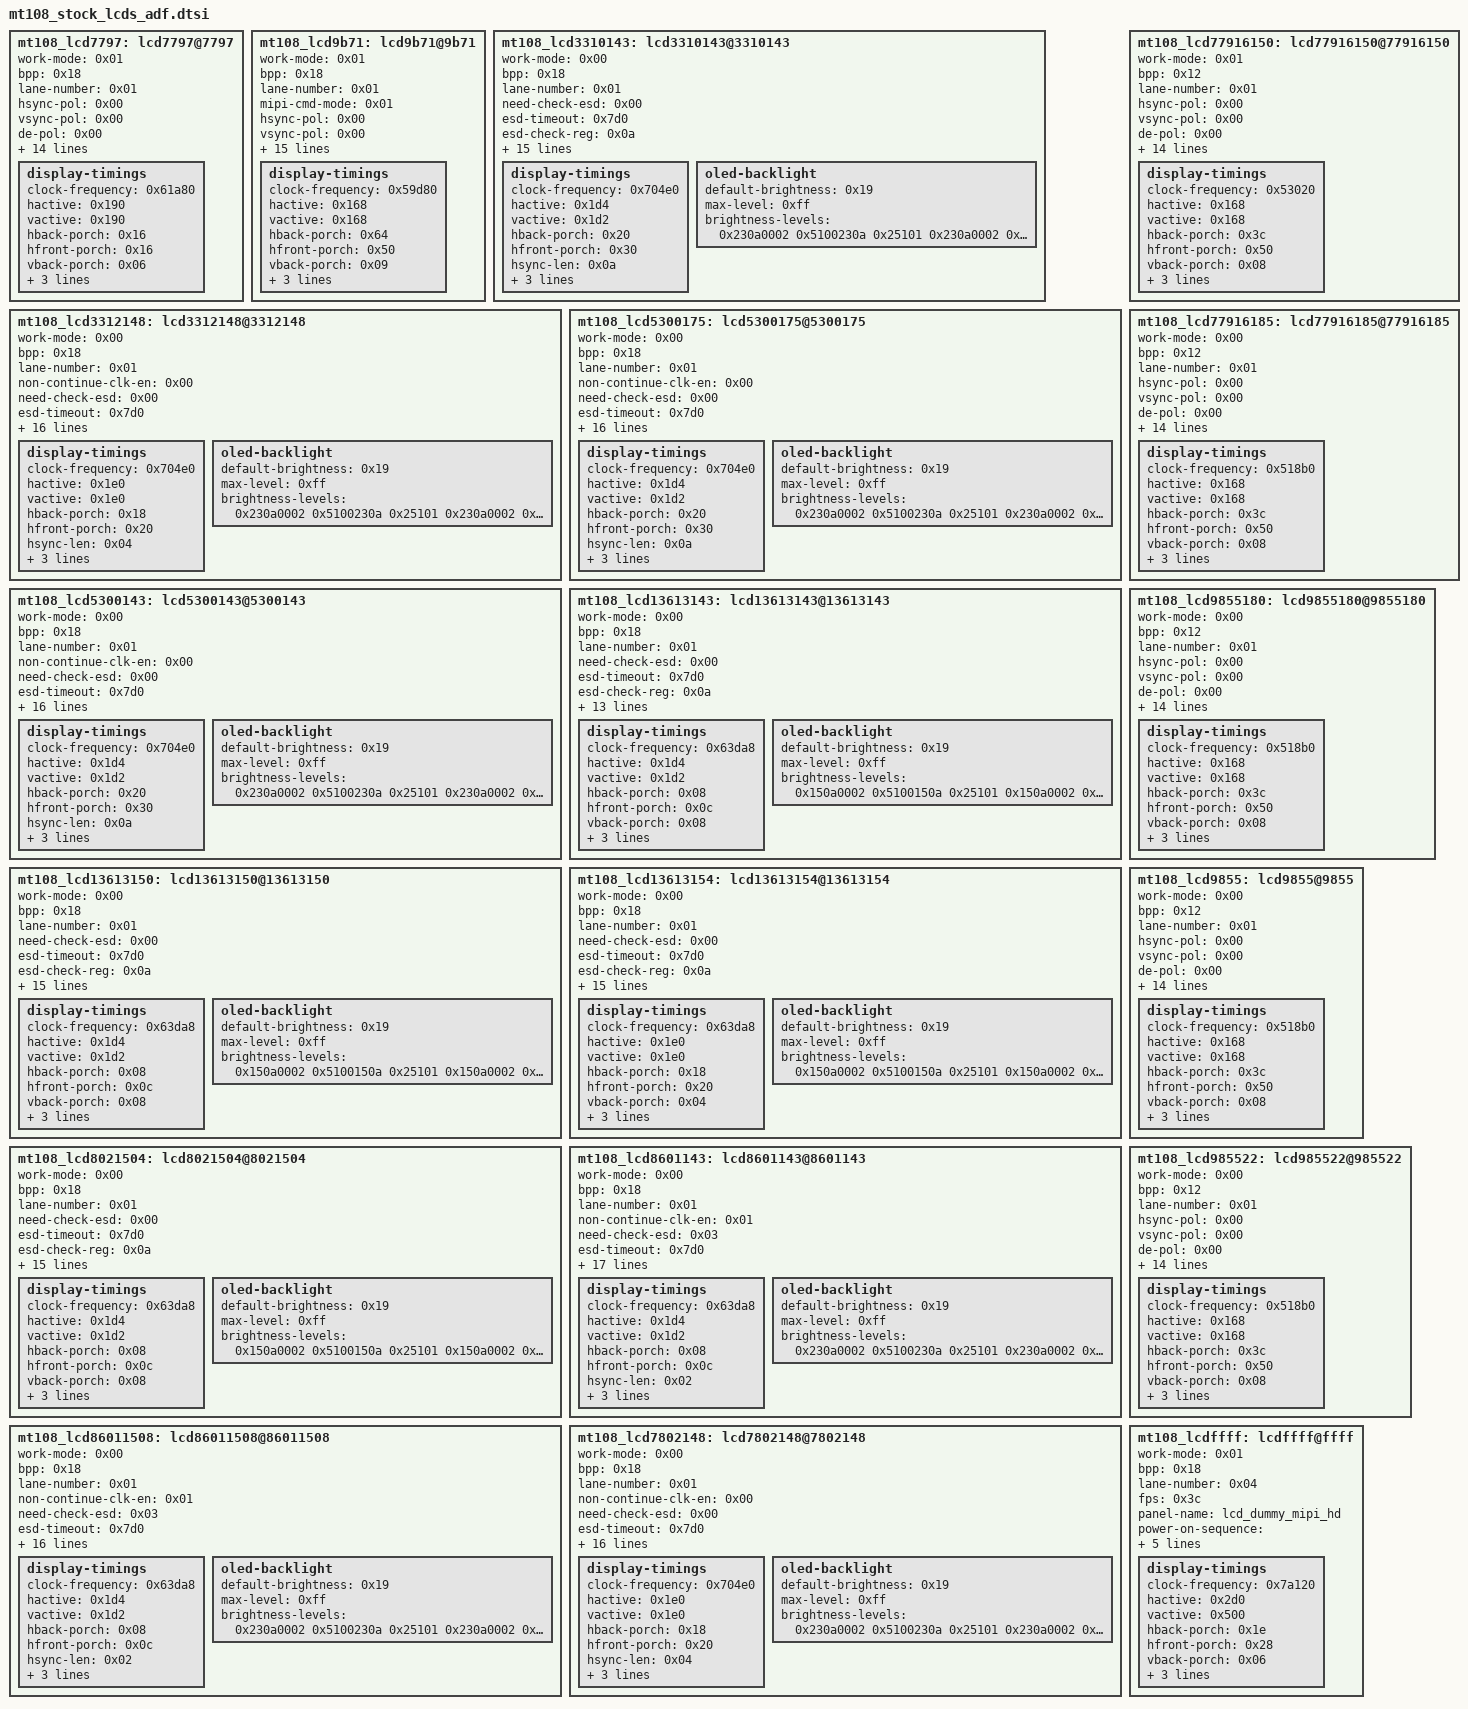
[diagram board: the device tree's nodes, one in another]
// SPDX-License-Identifier: GPL-2.0
/*
 * Stock /lcds panel nodes, generated by devices/stock_lcds_to_dtsi.py
 * from the stock DT; include inside a "lcds" node.
 */

	mt108_lcd7797: lcd7797@7797 {
		work-mode = <0x01>;
		bpp = <0x18>;
		lane-number = <0x01>;
		hsync-pol = <0x00>;
		vsync-pol = <0x00>;
		de-pol = <0x00>;
		te-pol = <0x00>;
		color-mode-pol = <0x01>;
		shut-down-pol = <0x01>;
		need-check-esd = <0x00>;
		esd-timeout = <0x3e8>;
		fps = <0x3c>;
		panel-name = "lcd_st7797_mipi";
		power-on-sequence = <0x32 0x01 0x05 0x32 0x00 0x05 0x32 0x01 0x14>;
		power-off-sequence = <0x32 0x00 0x14>;
		init-data = [23 00 00 02 f0 c3 23 00 00 02 f0 96 23 00 00 02 f0 a5 29 00 00 05 c1 bb 02 0f 0b 29 00 00 05 c2 bb 02 0f 0b 29 00 00 05 c3 11 03 24 01 29 00 00 05 c4 11 03 24 01 23 00 00 02 c5 2e 29 00 00 0f e0 f0 05 0a 0c 0a 07 34 73 4b 0e 1b 19 29 2a 29 00 00 0f e1 f0 05 0a 0c 0a 06 33 03 4c 0e 1c 1a 29 2a 29 00 00 03 e4 c8 20 29 00 00 0d e5 0f f5 00 11 22 25 10 77 77 77 44 44 29 00 00 0d e6 0f f5 00 11 22 25 10 22 22 22 22 22 29 00 00 08 e7 00 77 1f cc 2a 80 33 29 00 00 08 ec 00 55 00 00 00 49 22 23 00 00 02 ed c3 29 00 00 03 e4 08 2f 23 00 00 02 b2 10 23 00 00 02 b3 02 23 00 00 02 b4 02 29 00 00 05 b5 00 54 00 54 29 00 00 03 b6 c7 31 29 00 00 08 ba 5b aa 02 00 21 01 00 29 00 00 09 bb 00 28 00 28 08 07 07 04 29 00 00 09 bc 00 36 00 28 08 07 07 04 29 00 00 0c bd 77 ff ff ff ba ab ff ff 16 ff 02 29 00 00 04 a4 c0 4a e0 29 00 00 0a a5 20 12 40 01 00 06 2a 0a 00 29 00 00 0a a6 20 12 40 01 00 06 2a 0a 00 23 00 00 02 d9 22 13 00 00 01 21 23 00 00 02 35 00 23 00 00 02 36 0c 23 00 00 02 3a 07 23 78 00 02 11 00 23 78 00 02 29 00];
		sleep-in = [13 0a 00 01 28 13 78 00 01 10];
		sleep-out = [13 78 00 01 11 13 64 00 01 29];

		display-timings {
			clock-frequency = <0x61a80>;
			hactive = <0x190>;
			vactive = <0x190>;
			hback-porch = <0x16>;
			hfront-porch = <0x16>;
			vback-porch = <0x06>;
			vfront-porch = <0x06>;
			hsync-len = <0x0a>;
			vsync-len = <0x02>;
		};
	};

	mt108_lcd9b71: lcd9b71@9b71 {
		work-mode = <0x01>;
		bpp = <0x18>;
		lane-number = <0x01>;
		mipi-cmd-mode = <0x01>;
		hsync-pol = <0x00>;
		vsync-pol = <0x00>;
		de-pol = <0x00>;
		te-pol = <0x00>;
		color-mode-pol = <0x01>;
		shut-down-pol = <0x01>;
		need-check-esd = <0x00>;
		esd-timeout = <0x3e8>;
		fps = <0x3b>;
		panel-name = "lcd_gc9b71_mipi_boe1389";
		power-on-sequence = <0x32 0x01 0x32 0x32 0x00 0x32 0x32 0x01 0x78>;
		power-off-sequence = <0x32 0x00 0x78>;
		init-data = [05 00 00 01 fe 05 00 00 01 ef 15 00 00 02 80 19 15 00 00 02 81 30 15 00 00 02 82 09 15 00 00 02 83 03 15 00 00 02 84 73 15 00 00 02 89 18 15 00 00 02 8a 40 15 00 00 02 8b 0a 15 00 00 02 3a 07 15 00 00 02 36 00 15 00 00 02 ec 07 39 00 00 08 74 01 68 d8 00 00 4e 00 15 00 00 02 98 3e 15 00 00 02 99 3e 39 00 00 03 a1 01 04 39 00 00 03 a2 01 04 15 00 00 02 cb 02 39 00 00 03 7c b6 24 15 00 00 02 ac 34 15 00 00 02 f6 c8 39 00 00 03 b5 0c 0c 39 00 00 03 eb 01 67 15 00 00 02 b0 81 39 00 00 03 73 10 03 39 00 00 05 60 38 0e 1f 56 39 00 00 05 63 38 10 1f 56 39 00 00 07 64 38 12 72 ea 1f 56 39 00 00 07 66 38 16 72 ee 1f 56 39 00 00 08 68 00 0a ee 0a ee 1c 1c 39 00 00 08 69 00 0a f2 0a f2 1c 1c 39 05 00 21 6e 07 01 1a 00 0b 0b 09 09 13 13 11 11 19 1e 1d 00 00 1d 1e 19 12 12 14 14 0a 0a 0c 0c 00 1a 02 08 39 00 00 08 6c cc 0c cc 84 cc 04 50 15 00 00 02 7d 72 15 00 00 02 b4 0a 39 00 00 0b 70 02 03 09 07 09 03 09 07 09 03 39 00 00 05 90 06 06 05 06 39 00 00 04 93 45 ff 00 39 00 00 03 fb 00 00 39 00 00 03 fb 00 00 15 00 00 02 c3 16 15 00 00 02 c4 30 15 00 00 02 c9 3f 39 01 00 07 f0 4f 0d 0a 0f 00 34 39 01 00 07 f2 4f 0e 09 0e 00 35 39 01 00 07 f1 49 93 7c 2d 2f ff 39 01 00 07 f3 49 92 7c 2d 2f ff 15 00 00 02 be 11 05 00 00 01 fe 05 00 00 01 ee 05 78 00 01 11 05 14 00 01 29 39 00 00 05 2c 00 00 00 00 39 14 00 05 2c 00 00 00 00];
		sleep-in = [05 0a 00 01 28 05 78 00 01 10];
		sleep-out = [05 78 00 01 11 05 64 00 01 29];

		display-timings {
			clock-frequency = <0x59d80>;
			hactive = <0x168>;
			vactive = <0x168>;
			hback-porch = <0x64>;
			hfront-porch = <0x50>;
			vback-porch = <0x09>;
			vfront-porch = <0x08>;
			hsync-len = <0x1e>;
			vsync-len = <0x02>;
		};
	};

	mt108_lcd3310143: lcd3310143@3310143 {
		work-mode = <0x00>;
		bpp = <0x18>;
		lane-number = <0x01>;
		need-check-esd = <0x00>;
		esd-timeout = <0x7d0>;
		esd-check-reg = <0x0a>;
		esd-return-code = <0x9c>;
		fps = <0x3c>;
		width-mm = <0x44>;
		height-mm = <0x79>;
		panel-name = "lcd_icna3310_oled143_mipi";
		power-on-sequence = <0x21 0x01 0x14 0x32 0x01 0x14 0x32 0x00 0x14 0x32 0x01 0x32>;
		power-off-sequence = <0x32 0x00 0x14 0x21 0x00 0x14>;
		init-data = [23 00 00 02 fe 20 23 00 00 02 f4 5a 23 00 00 02 f5 59 23 00 00 02 fe e0 23 00 00 02 02 20 23 00 00 02 04 25 23 00 00 02 0b 20 23 00 00 02 0c 25 23 00 00 02 11 14 23 00 00 02 fe 00 23 00 00 02 35 00 23 00 00 02 3a 77 23 00 00 02 51 00 23 00 00 02 53 20 23 00 00 02 63 ff 29 00 00 05 2a 00 06 01 d9 29 00 00 05 2b 00 00 01 d1 13 78 00 01 11 13 14 00 01 29];
		aod-in = [23 00 00 02 fe 00 13 0a 00 01 39];
		aod-out = [23 00 00 02 fe 00 13 0a 00 01 38];
		sleep-in = [13 0a 00 01 28 13 78 00 01 10];
		sleep-out = [13 78 00 01 11 13 32 00 01 29];

		display-timings {
			clock-frequency = <0x704e0>;
			hactive = <0x1d4>;
			vactive = <0x1d2>;
			hback-porch = <0x20>;
			hfront-porch = <0x30>;
			hsync-len = <0x0a>;
			vfront-porch = <0x08>;
			vback-porch = <0x04>;
			vsync-len = <0x02>;
		};

		oled-backlight {
			default-brightness = <0x19>;
			max-level = <0xff>;
			brightness-levels = <0x230a0002 0x5100230a 0x25101 0x230a0002 0x5102230a 0x25103 0x230a0002 0x5104230a 0x25105 0x230a0002 0x5106230a 0x25107 0x230a0002 0x5108230a 0x25109 0x230a0002 0x510a230a 0x2510b 0x230a0002 0x510c230a 0x2510d 0x230a0002 0x510e230a 0x2510f 0x230a0002 0x5110230a 0x25111 0x230a0002 0x5112230a 0x25113 0x230a0002 0x5114230a 0x25115 0x230a0002 0x5116230a 0x25117 0x230a0002 0x5118230a 0x25119 0x230a0002 0x511a230a 0x2511b 0x230a0002 0x511c230a 0x2511d 0x230a0002 0x511e230a 0x2511f 0x230a0002 0x5120230a 0x25121 0x230a0002 0x5122230a 0x25123 0x230a0002 0x5124230a 0x25125 0x230a0002 0x5126230a 0x25127 0x230a0002 0x5128230a 0x25129 0x230a0002 0x512a230a 0x2512b 0x230a0002 0x512c230a 0x2512d 0x230a0002 0x512e230a 0x2512f 0x230a0002 0x5130230a 0x25131 0x230a0002 0x5132230a 0x25133 0x230a0002 0x5134230a 0x25135 0x230a0002 0x5136230a 0x25137 0x230a0002 0x5138230a 0x25139 0x230a0002 0x513a230a 0x2513b 0x230a0002 0x513c230a 0x2513d 0x230a0002 0x513e230a 0x2513f 0x230a0002 0x5140230a 0x25141 0x230a0002 0x5142230a 0x25143 0x230a0002 0x5144230a 0x25145 0x230a0002 0x5146230a 0x25147 0x230a0002 0x5148230a 0x25149 0x230a0002 0x514a230a 0x2514b 0x230a0002 0x514c230a 0x2514d 0x230a0002 0x514e230a 0x2514f 0x230a0002 0x5150230a 0x25151 0x230a0002 0x5152230a 0x25153 0x230a0002 0x5154230a 0x25155 0x230a0002 0x5156230a 0x25157 0x230a0002 0x5158230a 0x25159 0x230a0002 0x515a230a 0x2515b 0x230a0002 0x515c230a 0x2515d 0x230a0002 0x515e230a 0x2515f 0x230a0002 0x5160230a 0x25161 0x230a0002 0x5162230a 0x25163 0x230a0002 0x5164230a 0x25165 0x230a0002 0x5166230a 0x25167 0x230a0002 0x5168230a 0x25169 0x230a0002 0x516a230a 0x2516b 0x230a0002 0x516c230a 0x2516d 0x230a0002 0x516e230a 0x2516f 0x230a0002 0x5170230a 0x25171 0x230a0002 0x5172230a 0x25173 0x230a0002 0x5174230a 0x25175 0x230a0002 0x5176230a 0x25177 0x230a0002 0x5178230a 0x25179 0x230a0002 0x517a230a 0x2517b 0x230a0002 0x517c230a 0x2517d 0x230a0002 0x517e230a 0x2517f 0x230a0002 0x5180230a 0x25181 0x230a0002 0x5182230a 0x25183 0x230a0002 0x5184230a 0x25185 0x230a0002 0x5186230a 0x25187 0x230a0002 0x5188230a 0x25189 0x230a0002 0x518a230a 0x2518b 0x230a0002 0x518c230a 0x2518d 0x230a0002 0x518e230a 0x2518f 0x230a0002 0x5190230a 0x25191 0x230a0002 0x5192230a 0x25193 0x230a0002 0x5194230a 0x25195 0x230a0002 0x5196230a 0x25197 0x230a0002 0x5198230a 0x25199 0x230a0002 0x519a230a 0x2519b 0x230a0002 0x519c230a 0x2519d 0x230a0002 0x519e230a 0x2519f 0x230a0002 0x51a0230a 0x251a1 0x230a0002 0x51a2230a 0x251a3 0x230a0002 0x51a4230a 0x251a5 0x230a0002 0x51a6230a 0x251a7 0x230a0002 0x51a8230a 0x251a9 0x230a0002 0x51aa230a 0x251ab 0x230a0002 0x51ac230a 0x251ad 0x230a0002 0x51ae230a 0x251af 0x230a0002 0x51b0230a 0x251b1 0x230a0002 0x51b2230a 0x251b3 0x230a0002 0x51b4230a 0x251b5 0x230a0002 0x51b6230a 0x251b7 0x230a0002 0x51b8230a 0x251b9 0x230a0002 0x51ba230a 0x251bb 0x230a0002 0x51bc230a 0x251bd 0x230a0002 0x51be230a 0x251bf 0x230a0002 0x51c0230a 0x251c1 0x230a0002 0x51c2230a 0x251c3 0x230a0002 0x51c4230a 0x251c5 0x230a0002 0x51c6230a 0x251c7 0x230a0002 0x51c8230a 0x251c9 0x230a0002 0x51ca230a 0x251cb 0x230a0002 0x51cc230a 0x251cd 0x230a0002 0x51ce230a 0x251cf 0x230a0002 0x51d0230a 0x251d1 0x230a0002 0x51d2230a 0x251d3 0x230a0002 0x51d4230a 0x251d5 0x230a0002 0x51d6230a 0x251d7 0x230a0002 0x51d8230a 0x251d9 0x230a0002 0x51da230a 0x251db 0x230a0002 0x51dc230a 0x251dd 0x230a0002 0x51de230a 0x251df 0x230a0002 0x51e0230a 0x251e1 0x230a0002 0x51e2230a 0x251e3 0x230a0002 0x51e4230a 0x251e5 0x230a0002 0x51e6230a 0x251e7 0x230a0002 0x51e8230a 0x251e9 0x230a0002 0x51ea230a 0x251eb 0x230a0002 0x51ec230a 0x251ed 0x230a0002 0x51ee230a 0x251ef 0x230a0002 0x51f0230a 0x251f1 0x230a0002 0x51f2230a 0x251f3 0x230a0002 0x51f4230a 0x251f5 0x230a0002 0x51f6230a 0x251f7 0x230a0002 0x51f8230a 0x251f9 0x230a0002 0x51fa230a 0x251fb 0x230a0002 0x51fc230a 0x251fd 0x230a0002 0x51fe230a 0x251ff>;
		};
	};

	mt108_lcd3312148: lcd3312148@3312148 {
		work-mode = <0x00>;
		bpp = <0x18>;
		lane-number = <0x01>;
		non-continue-clk-en = <0x00>;
		need-check-esd = <0x00>;
		esd-timeout = <0x7d0>;
		esd-check-reg = <0x0a>;
		esd-return-code = <0x9c>;
		fps = <0x3c>;
		width-mm = <0x44>;
		height-mm = <0x79>;
		panel-name = "lcd_icna3312_oled148_mipi";
		power-on-sequence = <0x21 0x01 0x14 0x32 0x01 0x14 0x32 0x00 0x14 0x32 0x01 0x32>;
		power-off-sequence = <0x32 0x00 0x14 0x21 0x00 0x14>;
		init-data = <0x23000002 0xfe002300 0x23500 0x23000002 0x3a772300 0x25100 0x23000002 0x53202300 0x263ff 0x29000005 0x2a000001 0xdf290000 0x52b0000 0x1df1378 0x11113 0x14000129>;
		aod-in = [23 00 00 02 fe 00 13 0a 00 01 39];
		aod-out = [23 00 00 02 fe 00 13 0a 00 01 38];
		sleep-in = [13 0a 00 01 28 13 78 00 01 10];
		sleep-out = [13 78 00 01 11 13 32 00 01 29];

		display-timings {
			clock-frequency = <0x704e0>;
			hactive = <0x1e0>;
			vactive = <0x1e0>;
			hback-porch = <0x18>;
			hfront-porch = <0x20>;
			hsync-len = <0x04>;
			vfront-porch = <0x08>;
			vback-porch = <0x04>;
			vsync-len = <0x02>;
		};

		oled-backlight {
			default-brightness = <0x19>;
			max-level = <0xff>;
			brightness-levels = <0x230a0002 0x5100230a 0x25101 0x230a0002 0x5102230a 0x25103 0x230a0002 0x5104230a 0x25105 0x230a0002 0x5106230a 0x25107 0x230a0002 0x5108230a 0x25109 0x230a0002 0x510a230a 0x2510b 0x230a0002 0x510c230a 0x2510d 0x230a0002 0x510e230a 0x2510f 0x230a0002 0x5110230a 0x25111 0x230a0002 0x5112230a 0x25113 0x230a0002 0x5114230a 0x25115 0x230a0002 0x5116230a 0x25117 0x230a0002 0x5118230a 0x25119 0x230a0002 0x511a230a 0x2511b 0x230a0002 0x511c230a 0x2511d 0x230a0002 0x511e230a 0x2511f 0x230a0002 0x5120230a 0x25121 0x230a0002 0x5122230a 0x25123 0x230a0002 0x5124230a 0x25125 0x230a0002 0x5126230a 0x25127 0x230a0002 0x5128230a 0x25129 0x230a0002 0x512a230a 0x2512b 0x230a0002 0x512c230a 0x2512d 0x230a0002 0x512e230a 0x2512f 0x230a0002 0x5130230a 0x25131 0x230a0002 0x5132230a 0x25133 0x230a0002 0x5134230a 0x25135 0x230a0002 0x5136230a 0x25137 0x230a0002 0x5138230a 0x25139 0x230a0002 0x513a230a 0x2513b 0x230a0002 0x513c230a 0x2513d 0x230a0002 0x513e230a 0x2513f 0x230a0002 0x5140230a 0x25141 0x230a0002 0x5142230a 0x25143 0x230a0002 0x5144230a 0x25145 0x230a0002 0x5146230a 0x25147 0x230a0002 0x5148230a 0x25149 0x230a0002 0x514a230a 0x2514b 0x230a0002 0x514c230a 0x2514d 0x230a0002 0x514e230a 0x2514f 0x230a0002 0x5150230a 0x25151 0x230a0002 0x5152230a 0x25153 0x230a0002 0x5154230a 0x25155 0x230a0002 0x5156230a 0x25157 0x230a0002 0x5158230a 0x25159 0x230a0002 0x515a230a 0x2515b 0x230a0002 0x515c230a 0x2515d 0x230a0002 0x515e230a 0x2515f 0x230a0002 0x5160230a 0x25161 0x230a0002 0x5162230a 0x25163 0x230a0002 0x5164230a 0x25165 0x230a0002 0x5166230a 0x25167 0x230a0002 0x5168230a 0x25169 0x230a0002 0x516a230a 0x2516b 0x230a0002 0x516c230a 0x2516d 0x230a0002 0x516e230a 0x2516f 0x230a0002 0x5170230a 0x25171 0x230a0002 0x5172230a 0x25173 0x230a0002 0x5174230a 0x25175 0x230a0002 0x5176230a 0x25177 0x230a0002 0x5178230a 0x25179 0x230a0002 0x517a230a 0x2517b 0x230a0002 0x517c230a 0x2517d 0x230a0002 0x517e230a 0x2517f 0x230a0002 0x5180230a 0x25181 0x230a0002 0x5182230a 0x25183 0x230a0002 0x5184230a 0x25185 0x230a0002 0x5186230a 0x25187 0x230a0002 0x5188230a 0x25189 0x230a0002 0x518a230a 0x2518b 0x230a0002 0x518c230a 0x2518d 0x230a0002 0x518e230a 0x2518f 0x230a0002 0x5190230a 0x25191 0x230a0002 0x5192230a 0x25193 0x230a0002 0x5194230a 0x25195 0x230a0002 0x5196230a 0x25197 0x230a0002 0x5198230a 0x25199 0x230a0002 0x519a230a 0x2519b 0x230a0002 0x519c230a 0x2519d 0x230a0002 0x519e230a 0x2519f 0x230a0002 0x51a0230a 0x251a1 0x230a0002 0x51a2230a 0x251a3 0x230a0002 0x51a4230a 0x251a5 0x230a0002 0x51a6230a 0x251a7 0x230a0002 0x51a8230a 0x251a9 0x230a0002 0x51aa230a 0x251ab 0x230a0002 0x51ac230a 0x251ad 0x230a0002 0x51ae230a 0x251af 0x230a0002 0x51b0230a 0x251b1 0x230a0002 0x51b2230a 0x251b3 0x230a0002 0x51b4230a 0x251b5 0x230a0002 0x51b6230a 0x251b7 0x230a0002 0x51b8230a 0x251b9 0x230a0002 0x51ba230a 0x251bb 0x230a0002 0x51bc230a 0x251bd 0x230a0002 0x51be230a 0x251bf 0x230a0002 0x51c0230a 0x251c1 0x230a0002 0x51c2230a 0x251c3 0x230a0002 0x51c4230a 0x251c5 0x230a0002 0x51c6230a 0x251c7 0x230a0002 0x51c8230a 0x251c9 0x230a0002 0x51ca230a 0x251cb 0x230a0002 0x51cc230a 0x251cd 0x230a0002 0x51ce230a 0x251cf 0x230a0002 0x51d0230a 0x251d1 0x230a0002 0x51d2230a 0x251d3 0x230a0002 0x51d4230a 0x251d5 0x230a0002 0x51d6230a 0x251d7 0x230a0002 0x51d8230a 0x251d9 0x230a0002 0x51da230a 0x251db 0x230a0002 0x51dc230a 0x251dd 0x230a0002 0x51de230a 0x251df 0x230a0002 0x51e0230a 0x251e1 0x230a0002 0x51e2230a 0x251e3 0x230a0002 0x51e4230a 0x251e5 0x230a0002 0x51e6230a 0x251e7 0x230a0002 0x51e8230a 0x251e9 0x230a0002 0x51ea230a 0x251eb 0x230a0002 0x51ec230a 0x251ed 0x230a0002 0x51ee230a 0x251ef 0x230a0002 0x51f0230a 0x251f1 0x230a0002 0x51f2230a 0x251f3 0x230a0002 0x51f4230a 0x251f5 0x230a0002 0x51f6230a 0x251f7 0x230a0002 0x51f8230a 0x251f9 0x230a0002 0x51fa230a 0x251fb 0x230a0002 0x51fc230a 0x251fd 0x230a0002 0x51fe230a 0x251ff>;
		};
	};

	mt108_lcd5300175: lcd5300175@5300175 {
		work-mode = <0x00>;
		bpp = <0x18>;
		lane-number = <0x01>;
		non-continue-clk-en = <0x00>;
		need-check-esd = <0x00>;
		esd-timeout = <0x7d0>;
		esd-check-reg = <0x0a>;
		esd-return-code = <0x9c>;
		fps = <0x3c>;
		width-mm = <0x44>;
		height-mm = <0x79>;
		panel-name = "lcd_co5300_oled175_mipi";
		power-on-sequence = <0x21 0x01 0x14 0x32 0x01 0x14 0x32 0x00 0x32 0x32 0x01 0x78>;
		power-off-sequence = <0x32 0x00 0x14 0x21 0x00 0x14>;
		init-data = <0x23000002 0xfe202300 0x2f45a 0x23000002 0xf5592300 0x2fe40 0x23000002 0xa0fc2300 0x26101 0x23000002 0x62e32300 0x2fe00 0x23000002 0x35002300 0x23a77 0x23000002 0x51002300 0x25320 0x23000002 0x63ff2900 0x52a00 0x601d929 0x52b 0x1d1 0x230a0002 0x51001378 0x11113 0x14000129>;
		aod-in = [23 00 00 02 fe 00 13 0a 00 01 39];
		aod-out = [23 00 00 02 fe 00 13 0a 00 01 38];
		sleep-in = [13 0a 00 01 28 13 78 00 01 10];
		sleep-out = [13 78 00 01 11 13 32 00 01 29];

		display-timings {
			clock-frequency = <0x704e0>;
			hactive = <0x1d4>;
			vactive = <0x1d2>;
			hback-porch = <0x20>;
			hfront-porch = <0x30>;
			hsync-len = <0x0a>;
			vfront-porch = <0x08>;
			vback-porch = <0x04>;
			vsync-len = <0x02>;
		};

		oled-backlight {
			default-brightness = <0x19>;
			max-level = <0xff>;
			brightness-levels = <0x230a0002 0x5100230a 0x25101 0x230a0002 0x5102230a 0x25103 0x230a0002 0x5104230a 0x25105 0x230a0002 0x5106230a 0x25107 0x230a0002 0x5108230a 0x25109 0x230a0002 0x510a230a 0x2510b 0x230a0002 0x510c230a 0x2510d 0x230a0002 0x510e230a 0x2510f 0x230a0002 0x5110230a 0x25111 0x230a0002 0x5112230a 0x25113 0x230a0002 0x5114230a 0x25115 0x230a0002 0x5116230a 0x25117 0x230a0002 0x5118230a 0x25119 0x230a0002 0x511a230a 0x2511b 0x230a0002 0x511c230a 0x2511d 0x230a0002 0x511e230a 0x2511f 0x230a0002 0x5120230a 0x25121 0x230a0002 0x5122230a 0x25123 0x230a0002 0x5124230a 0x25125 0x230a0002 0x5126230a 0x25127 0x230a0002 0x5128230a 0x25129 0x230a0002 0x512a230a 0x2512b 0x230a0002 0x512c230a 0x2512d 0x230a0002 0x512e230a 0x2512f 0x230a0002 0x5130230a 0x25131 0x230a0002 0x5132230a 0x25133 0x230a0002 0x5134230a 0x25135 0x230a0002 0x5136230a 0x25137 0x230a0002 0x5138230a 0x25139 0x230a0002 0x513a230a 0x2513b 0x230a0002 0x513c230a 0x2513d 0x230a0002 0x513e230a 0x2513f 0x230a0002 0x5140230a 0x25141 0x230a0002 0x5142230a 0x25143 0x230a0002 0x5144230a 0x25145 0x230a0002 0x5146230a 0x25147 0x230a0002 0x5148230a 0x25149 0x230a0002 0x514a230a 0x2514b 0x230a0002 0x514c230a 0x2514d 0x230a0002 0x514e230a 0x2514f 0x230a0002 0x5150230a 0x25151 0x230a0002 0x5152230a 0x25153 0x230a0002 0x5154230a 0x25155 0x230a0002 0x5156230a 0x25157 0x230a0002 0x5158230a 0x25159 0x230a0002 0x515a230a 0x2515b 0x230a0002 0x515c230a 0x2515d 0x230a0002 0x515e230a 0x2515f 0x230a0002 0x5160230a 0x25161 0x230a0002 0x5162230a 0x25163 0x230a0002 0x5164230a 0x25165 0x230a0002 0x5166230a 0x25167 0x230a0002 0x5168230a 0x25169 0x230a0002 0x516a230a 0x2516b 0x230a0002 0x516c230a 0x2516d 0x230a0002 0x516e230a 0x2516f 0x230a0002 0x5170230a 0x25171 0x230a0002 0x5172230a 0x25173 0x230a0002 0x5174230a 0x25175 0x230a0002 0x5176230a 0x25177 0x230a0002 0x5178230a 0x25179 0x230a0002 0x517a230a 0x2517b 0x230a0002 0x517c230a 0x2517d 0x230a0002 0x517e230a 0x2517f 0x230a0002 0x5180230a 0x25181 0x230a0002 0x5182230a 0x25183 0x230a0002 0x5184230a 0x25185 0x230a0002 0x5186230a 0x25187 0x230a0002 0x5188230a 0x25189 0x230a0002 0x518a230a 0x2518b 0x230a0002 0x518c230a 0x2518d 0x230a0002 0x518e230a 0x2518f 0x230a0002 0x5190230a 0x25191 0x230a0002 0x5192230a 0x25193 0x230a0002 0x5194230a 0x25195 0x230a0002 0x5196230a 0x25197 0x230a0002 0x5198230a 0x25199 0x230a0002 0x519a230a 0x2519b 0x230a0002 0x519c230a 0x2519d 0x230a0002 0x519e230a 0x2519f 0x230a0002 0x51a0230a 0x251a1 0x230a0002 0x51a2230a 0x251a3 0x230a0002 0x51a4230a 0x251a5 0x230a0002 0x51a6230a 0x251a7 0x230a0002 0x51a8230a 0x251a9 0x230a0002 0x51aa230a 0x251ab 0x230a0002 0x51ac230a 0x251ad 0x230a0002 0x51ae230a 0x251af 0x230a0002 0x51b0230a 0x251b1 0x230a0002 0x51b2230a 0x251b3 0x230a0002 0x51b4230a 0x251b5 0x230a0002 0x51b6230a 0x251b7 0x230a0002 0x51b8230a 0x251b9 0x230a0002 0x51ba230a 0x251bb 0x230a0002 0x51bc230a 0x251bd 0x230a0002 0x51be230a 0x251bf 0x230a0002 0x51c0230a 0x251c1 0x230a0002 0x51c2230a 0x251c3 0x230a0002 0x51c4230a 0x251c5 0x230a0002 0x51c6230a 0x251c7 0x230a0002 0x51c8230a 0x251c9 0x230a0002 0x51ca230a 0x251cb 0x230a0002 0x51cc230a 0x251cd 0x230a0002 0x51ce230a 0x251cf 0x230a0002 0x51d0230a 0x251d1 0x230a0002 0x51d2230a 0x251d3 0x230a0002 0x51d4230a 0x251d5 0x230a0002 0x51d6230a 0x251d7 0x230a0002 0x51d8230a 0x251d9 0x230a0002 0x51da230a 0x251db 0x230a0002 0x51dc230a 0x251dd 0x230a0002 0x51de230a 0x251df 0x230a0002 0x51e0230a 0x251e1 0x230a0002 0x51e2230a 0x251e3 0x230a0002 0x51e4230a 0x251e5 0x230a0002 0x51e6230a 0x251e7 0x230a0002 0x51e8230a 0x251e9 0x230a0002 0x51ea230a 0x251eb 0x230a0002 0x51ec230a 0x251ed 0x230a0002 0x51ee230a 0x251ef 0x230a0002 0x51f0230a 0x251f1 0x230a0002 0x51f2230a 0x251f3 0x230a0002 0x51f4230a 0x251f5 0x230a0002 0x51f6230a 0x251f7 0x230a0002 0x51f8230a 0x251f9 0x230a0002 0x51fa230a 0x251fb 0x230a0002 0x51fc230a 0x251fd 0x230a0002 0x51fe230a 0x251ff>;
		};
	};

	mt108_lcd5300143: lcd5300143@5300143 {
		work-mode = <0x00>;
		bpp = <0x18>;
		lane-number = <0x01>;
		non-continue-clk-en = <0x00>;
		need-check-esd = <0x00>;
		esd-timeout = <0x7d0>;
		esd-check-reg = <0x0a>;
		esd-return-code = <0x9c>;
		fps = <0x3c>;
		width-mm = <0x44>;
		height-mm = <0x79>;
		panel-name = "lcd_co5300_oled143_mipi";
		power-on-sequence = <0x21 0x01 0x14 0x32 0x01 0x14 0x32 0x00 0x32 0x32 0x01 0x78>;
		power-off-sequence = <0x32 0x00 0x14 0x21 0x00 0x14>;
		init-data = <0x23000002 0xfe202300 0x2f45a 0x23000002 0xf5592300 0x2fe40 0x23000002 0xa0fc2300 0x2fe00 0x23000002 0x35002300 0x23a77 0x23000002 0x51002300 0x25320 0x23000002 0x63ff2900 0x52a00 0x601d929 0x52b 0x1d1 0x230a0002 0x51001378 0x11113 0x14000129>;
		aod-in = [23 00 00 02 fe 00 13 0a 00 01 39];
		aod-out = [23 00 00 02 fe 00 13 0a 00 01 38];
		sleep-in = [13 0a 00 01 28 13 78 00 01 10];
		sleep-out = [13 78 00 01 11 13 32 00 01 29];

		display-timings {
			clock-frequency = <0x704e0>;
			hactive = <0x1d4>;
			vactive = <0x1d2>;
			hback-porch = <0x20>;
			hfront-porch = <0x30>;
			hsync-len = <0x0a>;
			vfront-porch = <0x08>;
			vback-porch = <0x04>;
			vsync-len = <0x02>;
		};

		oled-backlight {
			default-brightness = <0x19>;
			max-level = <0xff>;
			brightness-levels = <0x230a0002 0x5100230a 0x25101 0x230a0002 0x5102230a 0x25103 0x230a0002 0x5104230a 0x25105 0x230a0002 0x5106230a 0x25107 0x230a0002 0x5108230a 0x25109 0x230a0002 0x510a230a 0x2510b 0x230a0002 0x510c230a 0x2510d 0x230a0002 0x510e230a 0x2510f 0x230a0002 0x5110230a 0x25111 0x230a0002 0x5112230a 0x25113 0x230a0002 0x5114230a 0x25115 0x230a0002 0x5116230a 0x25117 0x230a0002 0x5118230a 0x25119 0x230a0002 0x511a230a 0x2511b 0x230a0002 0x511c230a 0x2511d 0x230a0002 0x511e230a 0x2511f 0x230a0002 0x5120230a 0x25121 0x230a0002 0x5122230a 0x25123 0x230a0002 0x5124230a 0x25125 0x230a0002 0x5126230a 0x25127 0x230a0002 0x5128230a 0x25129 0x230a0002 0x512a230a 0x2512b 0x230a0002 0x512c230a 0x2512d 0x230a0002 0x512e230a 0x2512f 0x230a0002 0x5130230a 0x25131 0x230a0002 0x5132230a 0x25133 0x230a0002 0x5134230a 0x25135 0x230a0002 0x5136230a 0x25137 0x230a0002 0x5138230a 0x25139 0x230a0002 0x513a230a 0x2513b 0x230a0002 0x513c230a 0x2513d 0x230a0002 0x513e230a 0x2513f 0x230a0002 0x5140230a 0x25141 0x230a0002 0x5142230a 0x25143 0x230a0002 0x5144230a 0x25145 0x230a0002 0x5146230a 0x25147 0x230a0002 0x5148230a 0x25149 0x230a0002 0x514a230a 0x2514b 0x230a0002 0x514c230a 0x2514d 0x230a0002 0x514e230a 0x2514f 0x230a0002 0x5150230a 0x25151 0x230a0002 0x5152230a 0x25153 0x230a0002 0x5154230a 0x25155 0x230a0002 0x5156230a 0x25157 0x230a0002 0x5158230a 0x25159 0x230a0002 0x515a230a 0x2515b 0x230a0002 0x515c230a 0x2515d 0x230a0002 0x515e230a 0x2515f 0x230a0002 0x5160230a 0x25161 0x230a0002 0x5162230a 0x25163 0x230a0002 0x5164230a 0x25165 0x230a0002 0x5166230a 0x25167 0x230a0002 0x5168230a 0x25169 0x230a0002 0x516a230a 0x2516b 0x230a0002 0x516c230a 0x2516d 0x230a0002 0x516e230a 0x2516f 0x230a0002 0x5170230a 0x25171 0x230a0002 0x5172230a 0x25173 0x230a0002 0x5174230a 0x25175 0x230a0002 0x5176230a 0x25177 0x230a0002 0x5178230a 0x25179 0x230a0002 0x517a230a 0x2517b 0x230a0002 0x517c230a 0x2517d 0x230a0002 0x517e230a 0x2517f 0x230a0002 0x5180230a 0x25181 0x230a0002 0x5182230a 0x25183 0x230a0002 0x5184230a 0x25185 0x230a0002 0x5186230a 0x25187 0x230a0002 0x5188230a 0x25189 0x230a0002 0x518a230a 0x2518b 0x230a0002 0x518c230a 0x2518d 0x230a0002 0x518e230a 0x2518f 0x230a0002 0x5190230a 0x25191 0x230a0002 0x5192230a 0x25193 0x230a0002 0x5194230a 0x25195 0x230a0002 0x5196230a 0x25197 0x230a0002 0x5198230a 0x25199 0x230a0002 0x519a230a 0x2519b 0x230a0002 0x519c230a 0x2519d 0x230a0002 0x519e230a 0x2519f 0x230a0002 0x51a0230a 0x251a1 0x230a0002 0x51a2230a 0x251a3 0x230a0002 0x51a4230a 0x251a5 0x230a0002 0x51a6230a 0x251a7 0x230a0002 0x51a8230a 0x251a9 0x230a0002 0x51aa230a 0x251ab 0x230a0002 0x51ac230a 0x251ad 0x230a0002 0x51ae230a 0x251af 0x230a0002 0x51b0230a 0x251b1 0x230a0002 0x51b2230a 0x251b3 0x230a0002 0x51b4230a 0x251b5 0x230a0002 0x51b6230a 0x251b7 0x230a0002 0x51b8230a 0x251b9 0x230a0002 0x51ba230a 0x251bb 0x230a0002 0x51bc230a 0x251bd 0x230a0002 0x51be230a 0x251bf 0x230a0002 0x51c0230a 0x251c1 0x230a0002 0x51c2230a 0x251c3 0x230a0002 0x51c4230a 0x251c5 0x230a0002 0x51c6230a 0x251c7 0x230a0002 0x51c8230a 0x251c9 0x230a0002 0x51ca230a 0x251cb 0x230a0002 0x51cc230a 0x251cd 0x230a0002 0x51ce230a 0x251cf 0x230a0002 0x51d0230a 0x251d1 0x230a0002 0x51d2230a 0x251d3 0x230a0002 0x51d4230a 0x251d5 0x230a0002 0x51d6230a 0x251d7 0x230a0002 0x51d8230a 0x251d9 0x230a0002 0x51da230a 0x251db 0x230a0002 0x51dc230a 0x251dd 0x230a0002 0x51de230a 0x251df 0x230a0002 0x51e0230a 0x251e1 0x230a0002 0x51e2230a 0x251e3 0x230a0002 0x51e4230a 0x251e5 0x230a0002 0x51e6230a 0x251e7 0x230a0002 0x51e8230a 0x251e9 0x230a0002 0x51ea230a 0x251eb 0x230a0002 0x51ec230a 0x251ed 0x230a0002 0x51ee230a 0x251ef 0x230a0002 0x51f0230a 0x251f1 0x230a0002 0x51f2230a 0x251f3 0x230a0002 0x51f4230a 0x251f5 0x230a0002 0x51f6230a 0x251f7 0x230a0002 0x51f8230a 0x251f9 0x230a0002 0x51fa230a 0x251fb 0x230a0002 0x51fc230a 0x251fd 0x230a0002 0x51fe230a 0x251ff>;
		};
	};

	mt108_lcd13613143: lcd13613143@13613143 {
		work-mode = <0x00>;
		bpp = <0x18>;
		lane-number = <0x01>;
		need-check-esd = <0x00>;
		esd-timeout = <0x7d0>;
		esd-check-reg = <0x0a>;
		esd-return-code = <0x9c>;
		fps = <0x3c>;
		width-mm = <0x44>;
		height-mm = <0x79>;
		panel-name = "lcd_ch13613_oled143_mipi";
		power-on-sequence = <0x21 0x01 0x14 0x32 0x01 0x14 0x32 0x00 0x14 0x32 0x01 0x32>;
		power-off-sequence = <0x32 0x00 0x14 0x21 0x00 0x14>;
		init-data = [23 00 00 02 35 00 23 00 00 02 3a 07 23 00 00 02 64 00 29 00 00 05 2a 00 06 01 d9 29 00 00 05 2b 00 00 01 d1 23 00 00 02 f0 50 29 00 00 03 b3 65 08 23 00 00 02 b9 00 29 00 00 03 b0 04 04 23 00 00 02 f0 53 29 00 00 09 b1 a4 00 f0 05 01 80 96 63 23 00 00 02 51 00 13 64 00 01 11 13 14 00 01 29];
		sleep-in = [13 0a 00 01 28 13 78 00 01 10];
		sleep-out = [13 78 00 01 11 13 32 00 01 29];

		display-timings {
			clock-frequency = <0x63da8>;
			hactive = <0x1d4>;
			vactive = <0x1d2>;
			hback-porch = <0x08>;
			hfront-porch = <0x0c>;
			vback-porch = <0x08>;
			vfront-porch = <0x06>;
			hsync-len = <0x02>;
			vsync-len = <0x02>;
		};

		oled-backlight {
			default-brightness = <0x19>;
			max-level = <0xff>;
			brightness-levels = <0x150a0002 0x5100150a 0x25101 0x150a0002 0x5102150a 0x25103 0x150a0002 0x5104150a 0x25105 0x150a0002 0x5106150a 0x25107 0x150a0002 0x5108150a 0x25109 0x150a0002 0x510a150a 0x2510b 0x150a0002 0x510c150a 0x2510d 0x150a0002 0x510e150a 0x2510f 0x150a0002 0x5110150a 0x25111 0x150a0002 0x5112150a 0x25113 0x150a0002 0x5114150a 0x25115 0x150a0002 0x5116150a 0x25117 0x150a0002 0x5118150a 0x25119 0x150a0002 0x511a150a 0x2511b 0x150a0002 0x511c150a 0x2511d 0x150a0002 0x511e150a 0x2511f 0x150a0002 0x5120150a 0x25121 0x150a0002 0x5122150a 0x25123 0x150a0002 0x5124150a 0x25125 0x150a0002 0x5126150a 0x25127 0x150a0002 0x5128150a 0x25129 0x150a0002 0x512a150a 0x2512b 0x150a0002 0x512c150a 0x2512d 0x150a0002 0x512e150a 0x2512f 0x150a0002 0x5130150a 0x25131 0x150a0002 0x5132150a 0x25133 0x150a0002 0x5134150a 0x25135 0x150a0002 0x5136150a 0x25137 0x150a0002 0x5138150a 0x25139 0x150a0002 0x513a150a 0x2513b 0x150a0002 0x513c150a 0x2513d 0x150a0002 0x513e150a 0x2513f 0x150a0002 0x5140150a 0x25141 0x150a0002 0x5142150a 0x25143 0x150a0002 0x5144150a 0x25145 0x150a0002 0x5146150a 0x25147 0x150a0002 0x5148150a 0x25149 0x150a0002 0x514a150a 0x2514b 0x150a0002 0x514c150a 0x2514d 0x150a0002 0x514e150a 0x2514f 0x150a0002 0x5150150a 0x25151 0x150a0002 0x5152150a 0x25153 0x150a0002 0x5154150a 0x25155 0x150a0002 0x5156150a 0x25157 0x150a0002 0x5158150a 0x25159 0x150a0002 0x515a150a 0x2515b 0x150a0002 0x515c150a 0x2515d 0x150a0002 0x515e150a 0x2515f 0x150a0002 0x5160150a 0x25161 0x150a0002 0x5162150a 0x25163 0x150a0002 0x5164150a 0x25165 0x150a0002 0x5166150a 0x25167 0x150a0002 0x5168150a 0x25169 0x150a0002 0x516a150a 0x2516b 0x150a0002 0x516c150a 0x2516d 0x150a0002 0x516e150a 0x2516f 0x150a0002 0x5170150a 0x25171 0x150a0002 0x5172150a 0x25173 0x150a0002 0x5174150a 0x25175 0x150a0002 0x5176150a 0x25177 0x150a0002 0x5178150a 0x25179 0x150a0002 0x517a150a 0x2517b 0x150a0002 0x517c150a 0x2517d 0x150a0002 0x517e150a 0x2517f 0x150a0002 0x5180150a 0x25181 0x150a0002 0x5182150a 0x25183 0x150a0002 0x5184150a 0x25185 0x150a0002 0x5186150a 0x25187 0x150a0002 0x5188150a 0x25189 0x150a0002 0x518a150a 0x2518b 0x150a0002 0x518c150a 0x2518d 0x150a0002 0x518e150a 0x2518f 0x150a0002 0x5190150a 0x25191 0x150a0002 0x5192150a 0x25193 0x150a0002 0x5194150a 0x25195 0x150a0002 0x5196150a 0x25197 0x150a0002 0x5198150a 0x25199 0x150a0002 0x519a150a 0x2519b 0x150a0002 0x519c150a 0x2519d 0x150a0002 0x519e150a 0x2519f 0x150a0002 0x51a0150a 0x251a1 0x150a0002 0x51a2150a 0x251a3 0x150a0002 0x51a4150a 0x251a5 0x150a0002 0x51a6150a 0x251a7 0x150a0002 0x51a8150a 0x251a9 0x150a0002 0x51aa150a 0x251ab 0x150a0002 0x51ac150a 0x251ad 0x150a0002 0x51ae150a 0x251af 0x150a0002 0x51b0150a 0x251b1 0x150a0002 0x51b2150a 0x251b3 0x150a0002 0x51b4150a 0x251b5 0x150a0002 0x51b6150a 0x251b7 0x150a0002 0x51b8150a 0x251b9 0x150a0002 0x51ba150a 0x251bb 0x150a0002 0x51bc150a 0x251bd 0x150a0002 0x51be150a 0x251bf 0x150a0002 0x51c0150a 0x251c1 0x150a0002 0x51c2150a 0x251c3 0x150a0002 0x51c4150a 0x251c5 0x150a0002 0x51c6150a 0x251c7 0x150a0002 0x51c8150a 0x251c9 0x150a0002 0x51ca150a 0x251cb 0x150a0002 0x51cc150a 0x251cd 0x150a0002 0x51ce150a 0x251cf 0x150a0002 0x51d0150a 0x251d1 0x150a0002 0x51d2150a 0x251d3 0x150a0002 0x51d4150a 0x251d5 0x150a0002 0x51d6150a 0x251d7 0x150a0002 0x51d8150a 0x251d9 0x150a0002 0x51da150a 0x251db 0x150a0002 0x51dc150a 0x251dd 0x150a0002 0x51de150a 0x251df 0x150a0002 0x51e0150a 0x251e1 0x150a0002 0x51e2150a 0x251e3 0x150a0002 0x51e4150a 0x251e5 0x150a0002 0x51e6150a 0x251e7 0x150a0002 0x51e8150a 0x251e9 0x150a0002 0x51ea150a 0x251eb 0x150a0002 0x51ec150a 0x251ed 0x150a0002 0x51ee150a 0x251ef 0x150a0002 0x51f0150a 0x251f1 0x150a0002 0x51f2150a 0x251f3 0x150a0002 0x51f4150a 0x251f5 0x150a0002 0x51f6150a 0x251f7 0x150a0002 0x51f8150a 0x251f9 0x150a0002 0x51fa150a 0x251fb 0x150a0002 0x51fc150a 0x251fd 0x150a0002 0x51fe150a 0x251ff>;
		};
	};

	mt108_lcd13613150: lcd13613150@13613150 {
		work-mode = <0x00>;
		bpp = <0x18>;
		lane-number = <0x01>;
		need-check-esd = <0x00>;
		esd-timeout = <0x7d0>;
		esd-check-reg = <0x0a>;
		esd-return-code = <0x9c>;
		fps = <0x3c>;
		width-mm = <0x44>;
		height-mm = <0x79>;
		panel-name = "lcd_ch13613_oled1504_mipi";
		power-on-sequence = <0x21 0x01 0x14 0x32 0x01 0x14 0x32 0x00 0x14 0x32 0x01 0x32>;
		power-off-sequence = <0x32 0x00 0x14 0x21 0x00 0x14>;
		init-data = [13 64 00 01 11 29 00 00 05 2a 00 00 01 d3 29 00 00 05 2b 00 00 01 d1 23 00 00 02 53 20 23 00 00 02 51 00 23 00 00 02 35 00 13 14 00 01 29];
		aod-in = [13 0a 00 01 39];
		aod-out = [13 0a 00 01 38];
		sleep-in = [13 0a 00 01 28 13 78 00 01 10];
		sleep-out = [13 78 00 01 11 13 32 00 01 29];

		display-timings {
			clock-frequency = <0x63da8>;
			hactive = <0x1d4>;
			vactive = <0x1d2>;
			hback-porch = <0x08>;
			hfront-porch = <0x0c>;
			vback-porch = <0x08>;
			vfront-porch = <0x06>;
			hsync-len = <0x02>;
			vsync-len = <0x02>;
		};

		oled-backlight {
			default-brightness = <0x19>;
			max-level = <0xff>;
			brightness-levels = <0x150a0002 0x5100150a 0x25101 0x150a0002 0x5102150a 0x25103 0x150a0002 0x5104150a 0x25105 0x150a0002 0x5106150a 0x25107 0x150a0002 0x5108150a 0x25109 0x150a0002 0x510a150a 0x2510b 0x150a0002 0x510c150a 0x2510d 0x150a0002 0x510e150a 0x2510f 0x150a0002 0x5110150a 0x25111 0x150a0002 0x5112150a 0x25113 0x150a0002 0x5114150a 0x25115 0x150a0002 0x5116150a 0x25117 0x150a0002 0x5118150a 0x25119 0x150a0002 0x511a150a 0x2511b 0x150a0002 0x511c150a 0x2511d 0x150a0002 0x511e150a 0x2511f 0x150a0002 0x5120150a 0x25121 0x150a0002 0x5122150a 0x25123 0x150a0002 0x5124150a 0x25125 0x150a0002 0x5126150a 0x25127 0x150a0002 0x5128150a 0x25129 0x150a0002 0x512a150a 0x2512b 0x150a0002 0x512c150a 0x2512d 0x150a0002 0x512e150a 0x2512f 0x150a0002 0x5130150a 0x25131 0x150a0002 0x5132150a 0x25133 0x150a0002 0x5134150a 0x25135 0x150a0002 0x5136150a 0x25137 0x150a0002 0x5138150a 0x25139 0x150a0002 0x513a150a 0x2513b 0x150a0002 0x513c150a 0x2513d 0x150a0002 0x513e150a 0x2513f 0x150a0002 0x5140150a 0x25141 0x150a0002 0x5142150a 0x25143 0x150a0002 0x5144150a 0x25145 0x150a0002 0x5146150a 0x25147 0x150a0002 0x5148150a 0x25149 0x150a0002 0x514a150a 0x2514b 0x150a0002 0x514c150a 0x2514d 0x150a0002 0x514e150a 0x2514f 0x150a0002 0x5150150a 0x25151 0x150a0002 0x5152150a 0x25153 0x150a0002 0x5154150a 0x25155 0x150a0002 0x5156150a 0x25157 0x150a0002 0x5158150a 0x25159 0x150a0002 0x515a150a 0x2515b 0x150a0002 0x515c150a 0x2515d 0x150a0002 0x515e150a 0x2515f 0x150a0002 0x5160150a 0x25161 0x150a0002 0x5162150a 0x25163 0x150a0002 0x5164150a 0x25165 0x150a0002 0x5166150a 0x25167 0x150a0002 0x5168150a 0x25169 0x150a0002 0x516a150a 0x2516b 0x150a0002 0x516c150a 0x2516d 0x150a0002 0x516e150a 0x2516f 0x150a0002 0x5170150a 0x25171 0x150a0002 0x5172150a 0x25173 0x150a0002 0x5174150a 0x25175 0x150a0002 0x5176150a 0x25177 0x150a0002 0x5178150a 0x25179 0x150a0002 0x517a150a 0x2517b 0x150a0002 0x517c150a 0x2517d 0x150a0002 0x517e150a 0x2517f 0x150a0002 0x5180150a 0x25181 0x150a0002 0x5182150a 0x25183 0x150a0002 0x5184150a 0x25185 0x150a0002 0x5186150a 0x25187 0x150a0002 0x5188150a 0x25189 0x150a0002 0x518a150a 0x2518b 0x150a0002 0x518c150a 0x2518d 0x150a0002 0x518e150a 0x2518f 0x150a0002 0x5190150a 0x25191 0x150a0002 0x5192150a 0x25193 0x150a0002 0x5194150a 0x25195 0x150a0002 0x5196150a 0x25197 0x150a0002 0x5198150a 0x25199 0x150a0002 0x519a150a 0x2519b 0x150a0002 0x519c150a 0x2519d 0x150a0002 0x519e150a 0x2519f 0x150a0002 0x51a0150a 0x251a1 0x150a0002 0x51a2150a 0x251a3 0x150a0002 0x51a4150a 0x251a5 0x150a0002 0x51a6150a 0x251a7 0x150a0002 0x51a8150a 0x251a9 0x150a0002 0x51aa150a 0x251ab 0x150a0002 0x51ac150a 0x251ad 0x150a0002 0x51ae150a 0x251af 0x150a0002 0x51b0150a 0x251b1 0x150a0002 0x51b2150a 0x251b3 0x150a0002 0x51b4150a 0x251b5 0x150a0002 0x51b6150a 0x251b7 0x150a0002 0x51b8150a 0x251b9 0x150a0002 0x51ba150a 0x251bb 0x150a0002 0x51bc150a 0x251bd 0x150a0002 0x51be150a 0x251bf 0x150a0002 0x51c0150a 0x251c1 0x150a0002 0x51c2150a 0x251c3 0x150a0002 0x51c4150a 0x251c5 0x150a0002 0x51c6150a 0x251c7 0x150a0002 0x51c8150a 0x251c9 0x150a0002 0x51ca150a 0x251cb 0x150a0002 0x51cc150a 0x251cd 0x150a0002 0x51ce150a 0x251cf 0x150a0002 0x51d0150a 0x251d1 0x150a0002 0x51d2150a 0x251d3 0x150a0002 0x51d4150a 0x251d5 0x150a0002 0x51d6150a 0x251d7 0x150a0002 0x51d8150a 0x251d9 0x150a0002 0x51da150a 0x251db 0x150a0002 0x51dc150a 0x251dd 0x150a0002 0x51de150a 0x251df 0x150a0002 0x51e0150a 0x251e1 0x150a0002 0x51e2150a 0x251e3 0x150a0002 0x51e4150a 0x251e5 0x150a0002 0x51e6150a 0x251e7 0x150a0002 0x51e8150a 0x251e9 0x150a0002 0x51ea150a 0x251eb 0x150a0002 0x51ec150a 0x251ed 0x150a0002 0x51ee150a 0x251ef 0x150a0002 0x51f0150a 0x251f1 0x150a0002 0x51f2150a 0x251f3 0x150a0002 0x51f4150a 0x251f5 0x150a0002 0x51f6150a 0x251f7 0x150a0002 0x51f8150a 0x251f9 0x150a0002 0x51fa150a 0x251fb 0x150a0002 0x51fc150a 0x251fd 0x150a0002 0x51fe150a 0x251ff>;
		};
	};

	mt108_lcd13613154: lcd13613154@13613154 {
		work-mode = <0x00>;
		bpp = <0x18>;
		lane-number = <0x01>;
		need-check-esd = <0x00>;
		esd-timeout = <0x7d0>;
		esd-check-reg = <0x0a>;
		esd-return-code = <0x9c>;
		fps = <0x3c>;
		width-mm = <0x44>;
		height-mm = <0x79>;
		panel-name = "lcd_ch13613_oled154_mipi";
		power-on-sequence = <0x21 0x01 0x14 0x32 0x01 0x14 0x32 0x00 0x14 0x32 0x01 0x32>;
		power-off-sequence = <0x32 0x00 0x14 0x21 0x00 0x14>;
		init-data = [29 00 00 05 2a 00 00 01 df 29 00 00 05 2b 00 00 01 df 23 00 00 02 35 00 23 00 00 02 36 00 23 00 00 02 3a 07 23 00 00 02 51 00 23 00 00 02 64 10 13 64 00 01 11 13 14 00 01 29];
		aod-in = [13 0a 00 01 39];
		aod-out = [13 0a 00 01 38];
		sleep-in = [13 0a 00 01 28 13 78 00 01 10];
		sleep-out = [13 78 00 01 11 13 32 00 01 29];

		display-timings {
			clock-frequency = <0x63da8>;
			hactive = <0x1e0>;
			vactive = <0x1e0>;
			hback-porch = <0x18>;
			hfront-porch = <0x20>;
			vback-porch = <0x04>;
			vfront-porch = <0x08>;
			hsync-len = <0x04>;
			vsync-len = <0x02>;
		};

		oled-backlight {
			default-brightness = <0x19>;
			max-level = <0xff>;
			brightness-levels = <0x150a0002 0x5100150a 0x25101 0x150a0002 0x5102150a 0x25103 0x150a0002 0x5104150a 0x25105 0x150a0002 0x5106150a 0x25107 0x150a0002 0x5108150a 0x25109 0x150a0002 0x510a150a 0x2510b 0x150a0002 0x510c150a 0x2510d 0x150a0002 0x510e150a 0x2510f 0x150a0002 0x5110150a 0x25111 0x150a0002 0x5112150a 0x25113 0x150a0002 0x5114150a 0x25115 0x150a0002 0x5116150a 0x25117 0x150a0002 0x5118150a 0x25119 0x150a0002 0x511a150a 0x2511b 0x150a0002 0x511c150a 0x2511d 0x150a0002 0x511e150a 0x2511f 0x150a0002 0x5120150a 0x25121 0x150a0002 0x5122150a 0x25123 0x150a0002 0x5124150a 0x25125 0x150a0002 0x5126150a 0x25127 0x150a0002 0x5128150a 0x25129 0x150a0002 0x512a150a 0x2512b 0x150a0002 0x512c150a 0x2512d 0x150a0002 0x512e150a 0x2512f 0x150a0002 0x5130150a 0x25131 0x150a0002 0x5132150a 0x25133 0x150a0002 0x5134150a 0x25135 0x150a0002 0x5136150a 0x25137 0x150a0002 0x5138150a 0x25139 0x150a0002 0x513a150a 0x2513b 0x150a0002 0x513c150a 0x2513d 0x150a0002 0x513e150a 0x2513f 0x150a0002 0x5140150a 0x25141 0x150a0002 0x5142150a 0x25143 0x150a0002 0x5144150a 0x25145 0x150a0002 0x5146150a 0x25147 0x150a0002 0x5148150a 0x25149 0x150a0002 0x514a150a 0x2514b 0x150a0002 0x514c150a 0x2514d 0x150a0002 0x514e150a 0x2514f 0x150a0002 0x5150150a 0x25151 0x150a0002 0x5152150a 0x25153 0x150a0002 0x5154150a 0x25155 0x150a0002 0x5156150a 0x25157 0x150a0002 0x5158150a 0x25159 0x150a0002 0x515a150a 0x2515b 0x150a0002 0x515c150a 0x2515d 0x150a0002 0x515e150a 0x2515f 0x150a0002 0x5160150a 0x25161 0x150a0002 0x5162150a 0x25163 0x150a0002 0x5164150a 0x25165 0x150a0002 0x5166150a 0x25167 0x150a0002 0x5168150a 0x25169 0x150a0002 0x516a150a 0x2516b 0x150a0002 0x516c150a 0x2516d 0x150a0002 0x516e150a 0x2516f 0x150a0002 0x5170150a 0x25171 0x150a0002 0x5172150a 0x25173 0x150a0002 0x5174150a 0x25175 0x150a0002 0x5176150a 0x25177 0x150a0002 0x5178150a 0x25179 0x150a0002 0x517a150a 0x2517b 0x150a0002 0x517c150a 0x2517d 0x150a0002 0x517e150a 0x2517f 0x150a0002 0x5180150a 0x25181 0x150a0002 0x5182150a 0x25183 0x150a0002 0x5184150a 0x25185 0x150a0002 0x5186150a 0x25187 0x150a0002 0x5188150a 0x25189 0x150a0002 0x518a150a 0x2518b 0x150a0002 0x518c150a 0x2518d 0x150a0002 0x518e150a 0x2518f 0x150a0002 0x5190150a 0x25191 0x150a0002 0x5192150a 0x25193 0x150a0002 0x5194150a 0x25195 0x150a0002 0x5196150a 0x25197 0x150a0002 0x5198150a 0x25199 0x150a0002 0x519a150a 0x2519b 0x150a0002 0x519c150a 0x2519d 0x150a0002 0x519e150a 0x2519f 0x150a0002 0x51a0150a 0x251a1 0x150a0002 0x51a2150a 0x251a3 0x150a0002 0x51a4150a 0x251a5 0x150a0002 0x51a6150a 0x251a7 0x150a0002 0x51a8150a 0x251a9 0x150a0002 0x51aa150a 0x251ab 0x150a0002 0x51ac150a 0x251ad 0x150a0002 0x51ae150a 0x251af 0x150a0002 0x51b0150a 0x251b1 0x150a0002 0x51b2150a 0x251b3 0x150a0002 0x51b4150a 0x251b5 0x150a0002 0x51b6150a 0x251b7 0x150a0002 0x51b8150a 0x251b9 0x150a0002 0x51ba150a 0x251bb 0x150a0002 0x51bc150a 0x251bd 0x150a0002 0x51be150a 0x251bf 0x150a0002 0x51c0150a 0x251c1 0x150a0002 0x51c2150a 0x251c3 0x150a0002 0x51c4150a 0x251c5 0x150a0002 0x51c6150a 0x251c7 0x150a0002 0x51c8150a 0x251c9 0x150a0002 0x51ca150a 0x251cb 0x150a0002 0x51cc150a 0x251cd 0x150a0002 0x51ce150a 0x251cf 0x150a0002 0x51d0150a 0x251d1 0x150a0002 0x51d2150a 0x251d3 0x150a0002 0x51d4150a 0x251d5 0x150a0002 0x51d6150a 0x251d7 0x150a0002 0x51d8150a 0x251d9 0x150a0002 0x51da150a 0x251db 0x150a0002 0x51dc150a 0x251dd 0x150a0002 0x51de150a 0x251df 0x150a0002 0x51e0150a 0x251e1 0x150a0002 0x51e2150a 0x251e3 0x150a0002 0x51e4150a 0x251e5 0x150a0002 0x51e6150a 0x251e7 0x150a0002 0x51e8150a 0x251e9 0x150a0002 0x51ea150a 0x251eb 0x150a0002 0x51ec150a 0x251ed 0x150a0002 0x51ee150a 0x251ef 0x150a0002 0x51f0150a 0x251f1 0x150a0002 0x51f2150a 0x251f3 0x150a0002 0x51f4150a 0x251f5 0x150a0002 0x51f6150a 0x251f7 0x150a0002 0x51f8150a 0x251f9 0x150a0002 0x51fa150a 0x251fb 0x150a0002 0x51fc150a 0x251fd 0x150a0002 0x51fe150a 0x251ff>;
		};
	};

	mt108_lcd8021504: lcd8021504@8021504 {
		work-mode = <0x00>;
		bpp = <0x18>;
		lane-number = <0x01>;
		need-check-esd = <0x00>;
		esd-timeout = <0x7d0>;
		esd-check-reg = <0x0a>;
		esd-return-code = <0x9c>;
		fps = <0x3c>;
		width-mm = <0x44>;
		height-mm = <0x79>;
		panel-name = "lcd_st802_oled1504_mipi";
		power-on-sequence = <0x21 0x01 0x14 0x32 0x01 0x14 0x32 0x00 0x14 0x32 0x01 0x32>;
		power-off-sequence = <0x32 0x00 0x14 0x21 0x00 0x14>;
		init-data = <0x13640001 0x11290000 0x52a0000 0x1d32900 0x52b00 0x1d123 0x253 0x20230000 0x2510023 0x23a 0x77230000 0x2350013 0x14000129>;
		aod-in = [13 0a 00 01 39];
		aod-out = [13 0a 00 01 38];
		sleep-in = [13 0a 00 01 28 13 78 00 01 10];
		sleep-out = [13 78 00 01 11 13 32 00 01 29];

		display-timings {
			clock-frequency = <0x63da8>;
			hactive = <0x1d4>;
			vactive = <0x1d2>;
			hback-porch = <0x08>;
			hfront-porch = <0x0c>;
			vback-porch = <0x08>;
			vfront-porch = <0x06>;
			hsync-len = <0x02>;
			vsync-len = <0x02>;
		};

		oled-backlight {
			default-brightness = <0x19>;
			max-level = <0xff>;
			brightness-levels = <0x150a0002 0x5100150a 0x25101 0x150a0002 0x5102150a 0x25103 0x150a0002 0x5104150a 0x25105 0x150a0002 0x5106150a 0x25107 0x150a0002 0x5108150a 0x25109 0x150a0002 0x510a150a 0x2510b 0x150a0002 0x510c150a 0x2510d 0x150a0002 0x510e150a 0x2510f 0x150a0002 0x5110150a 0x25111 0x150a0002 0x5112150a 0x25113 0x150a0002 0x5114150a 0x25115 0x150a0002 0x5116150a 0x25117 0x150a0002 0x5118150a 0x25119 0x150a0002 0x511a150a 0x2511b 0x150a0002 0x511c150a 0x2511d 0x150a0002 0x511e150a 0x2511f 0x150a0002 0x5120150a 0x25121 0x150a0002 0x5122150a 0x25123 0x150a0002 0x5124150a 0x25125 0x150a0002 0x5126150a 0x25127 0x150a0002 0x5128150a 0x25129 0x150a0002 0x512a150a 0x2512b 0x150a0002 0x512c150a 0x2512d 0x150a0002 0x512e150a 0x2512f 0x150a0002 0x5130150a 0x25131 0x150a0002 0x5132150a 0x25133 0x150a0002 0x5134150a 0x25135 0x150a0002 0x5136150a 0x25137 0x150a0002 0x5138150a 0x25139 0x150a0002 0x513a150a 0x2513b 0x150a0002 0x513c150a 0x2513d 0x150a0002 0x513e150a 0x2513f 0x150a0002 0x5140150a 0x25141 0x150a0002 0x5142150a 0x25143 0x150a0002 0x5144150a 0x25145 0x150a0002 0x5146150a 0x25147 0x150a0002 0x5148150a 0x25149 0x150a0002 0x514a150a 0x2514b 0x150a0002 0x514c150a 0x2514d 0x150a0002 0x514e150a 0x2514f 0x150a0002 0x5150150a 0x25151 0x150a0002 0x5152150a 0x25153 0x150a0002 0x5154150a 0x25155 0x150a0002 0x5156150a 0x25157 0x150a0002 0x5158150a 0x25159 0x150a0002 0x515a150a 0x2515b 0x150a0002 0x515c150a 0x2515d 0x150a0002 0x515e150a 0x2515f 0x150a0002 0x5160150a 0x25161 0x150a0002 0x5162150a 0x25163 0x150a0002 0x5164150a 0x25165 0x150a0002 0x5166150a 0x25167 0x150a0002 0x5168150a 0x25169 0x150a0002 0x516a150a 0x2516b 0x150a0002 0x516c150a 0x2516d 0x150a0002 0x516e150a 0x2516f 0x150a0002 0x5170150a 0x25171 0x150a0002 0x5172150a 0x25173 0x150a0002 0x5174150a 0x25175 0x150a0002 0x5176150a 0x25177 0x150a0002 0x5178150a 0x25179 0x150a0002 0x517a150a 0x2517b 0x150a0002 0x517c150a 0x2517d 0x150a0002 0x517e150a 0x2517f 0x150a0002 0x5180150a 0x25181 0x150a0002 0x5182150a 0x25183 0x150a0002 0x5184150a 0x25185 0x150a0002 0x5186150a 0x25187 0x150a0002 0x5188150a 0x25189 0x150a0002 0x518a150a 0x2518b 0x150a0002 0x518c150a 0x2518d 0x150a0002 0x518e150a 0x2518f 0x150a0002 0x5190150a 0x25191 0x150a0002 0x5192150a 0x25193 0x150a0002 0x5194150a 0x25195 0x150a0002 0x5196150a 0x25197 0x150a0002 0x5198150a 0x25199 0x150a0002 0x519a150a 0x2519b 0x150a0002 0x519c150a 0x2519d 0x150a0002 0x519e150a 0x2519f 0x150a0002 0x51a0150a 0x251a1 0x150a0002 0x51a2150a 0x251a3 0x150a0002 0x51a4150a 0x251a5 0x150a0002 0x51a6150a 0x251a7 0x150a0002 0x51a8150a 0x251a9 0x150a0002 0x51aa150a 0x251ab 0x150a0002 0x51ac150a 0x251ad 0x150a0002 0x51ae150a 0x251af 0x150a0002 0x51b0150a 0x251b1 0x150a0002 0x51b2150a 0x251b3 0x150a0002 0x51b4150a 0x251b5 0x150a0002 0x51b6150a 0x251b7 0x150a0002 0x51b8150a 0x251b9 0x150a0002 0x51ba150a 0x251bb 0x150a0002 0x51bc150a 0x251bd 0x150a0002 0x51be150a 0x251bf 0x150a0002 0x51c0150a 0x251c1 0x150a0002 0x51c2150a 0x251c3 0x150a0002 0x51c4150a 0x251c5 0x150a0002 0x51c6150a 0x251c7 0x150a0002 0x51c8150a 0x251c9 0x150a0002 0x51ca150a 0x251cb 0x150a0002 0x51cc150a 0x251cd 0x150a0002 0x51ce150a 0x251cf 0x150a0002 0x51d0150a 0x251d1 0x150a0002 0x51d2150a 0x251d3 0x150a0002 0x51d4150a 0x251d5 0x150a0002 0x51d6150a 0x251d7 0x150a0002 0x51d8150a 0x251d9 0x150a0002 0x51da150a 0x251db 0x150a0002 0x51dc150a 0x251dd 0x150a0002 0x51de150a 0x251df 0x150a0002 0x51e0150a 0x251e1 0x150a0002 0x51e2150a 0x251e3 0x150a0002 0x51e4150a 0x251e5 0x150a0002 0x51e6150a 0x251e7 0x150a0002 0x51e8150a 0x251e9 0x150a0002 0x51ea150a 0x251eb 0x150a0002 0x51ec150a 0x251ed 0x150a0002 0x51ee150a 0x251ef 0x150a0002 0x51f0150a 0x251f1 0x150a0002 0x51f2150a 0x251f3 0x150a0002 0x51f4150a 0x251f5 0x150a0002 0x51f6150a 0x251f7 0x150a0002 0x51f8150a 0x251f9 0x150a0002 0x51fa150a 0x251fb 0x150a0002 0x51fc150a 0x251fd 0x150a0002 0x51fe150a 0x251ff>;
		};
	};

	mt108_lcd8601143: lcd8601143@8601143 {
		work-mode = <0x00>;
		bpp = <0x18>;
		lane-number = <0x01>;
		non-continue-clk-en = <0x01>;
		need-check-esd = <0x03>;
		esd-timeout = <0x7d0>;
		esd-check-reg = <0x0a>;
		esd-return-code = <0x9c>;
		fps = <0x3c>;
		width-mm = <0x44>;
		height-mm = <0x79>;
		panel-name = "lcd_sh8601z_oled143_mipi";
		power-on-sequence = <0x21 0x01 0x14 0x32 0x01 0x14 0x32 0x00 0x32 0x32 0x01 0x78>;
		power-off-sequence = <0x32 0x00 0x14 0x21 0x00 0x14>;
		init-data = [29 00 00 03 c0 5a 5a 29 00 00 03 c1 5a 5a 23 00 00 02 e4 01 23 00 00 02 b0 31 23 00 00 02 b2 18 23 00 00 02 b0 06 23 00 00 02 e7 00 13 78 00 01 11 29 00 00 03 c0 5a 5a 29 00 00 03 c1 5a 5a 23 00 00 02 b0 04 29 00 00 03 b1 d4 01 23 00 00 02 b0 02 29 00 00 03 d3 d4 01 23 00 00 02 b0 03 23 00 00 02 f2 10 29 00 00 05 2a 00 00 01 d3 29 00 00 05 2b 00 00 01 d1 29 00 00 03 44 00 bc 23 00 00 02 35 00 23 00 00 02 3a 77 23 00 00 02 51 00 23 78 00 02 53 20 13 32 00 01 29];
		aod-in = <0x290a0089 0xcca600ff 0x7000000 0x09 0x10000f 0x2a004b 0x470082 0xe100db 0x9000e1 0xf3009d 0xe50003 0x1bd00f3 0x2201db 0x3013c 0x1fc0016 0x1560113 0x1260169 0x13c0144 0x18b0167 0x16501b0 0x184017e 0x1cb01bb 0x1b00103 0x2e801db 0x134020b 0x2fd015c 0x22f0221 0x287024f 0x24102ad 0x2890279 0x2f102b8 0x2a7022c 0x3e902d7 0x2690314 0x301039e 0x3290a00 0x89cda600 0xff070000 0x00 0x22003d00 0x39008000 0xe100d800 0x9900e300 0xff00b300 0xef001801 0xd100fe00 0x35010601 0x1d015e01 0x2f013a01 0x80015301 0x55019f01 0x74017001 0xbc01a801 0x9f01ef01 0xd401c801 0x1d02f701 0xea014502 0x38022a02 0x91026f02 0x6002d202 0x9d028d02 0xa03cc02 0xba024503 0xf502e202 0x78034403 0x3003d803 0x8f037903 0x3604d503 0xbd039004 0x1404f903 0xdf04290a 0x89cea6 0xff0700 0x00 0x7e00e1 0xd50096 0xe100fc 0xc900f9 0x2e01fb 0x150155 0x1240131 0x1770166 0x16401af 0x1980190 0x1de01c2 0x1b7010a 0x2e601d9 0x1320224 0x2160279 0x258024a 0x2b70287 0x27702ee 0x2d902c7 0x2560322 0x30f03af 0x3680352 0x30304aa 0x3930358 0x4e703ce 0x3a70464 0x4440442 0x5d804b5 0x4db0551 0x5260577 0x6ca059a 0x5160713 0xa000139>;
		aod-out = [13 0a 00 01 38];
		sleep-in = [13 0a 00 01 28 13 78 00 01 10];
		sleep-out = [13 78 00 01 11 13 32 00 01 29];

		display-timings {
			clock-frequency = <0x63da8>;
			hactive = <0x1d4>;
			vactive = <0x1d2>;
			hback-porch = <0x08>;
			hfront-porch = <0x0c>;
			hsync-len = <0x02>;
			vfront-porch = <0x08>;
			vback-porch = <0x07>;
			vsync-len = <0x01>;
		};

		oled-backlight {
			default-brightness = <0x19>;
			max-level = <0xff>;
			brightness-levels = <0x230a0002 0x5100230a 0x25101 0x230a0002 0x5102230a 0x25103 0x230a0002 0x5104230a 0x25105 0x230a0002 0x5106230a 0x25107 0x230a0002 0x5108230a 0x25109 0x230a0002 0x510a230a 0x2510b 0x230a0002 0x510c230a 0x2510d 0x230a0002 0x510e230a 0x2510f 0x230a0002 0x5110230a 0x25111 0x230a0002 0x5112230a 0x25113 0x230a0002 0x5114230a 0x25115 0x230a0002 0x5116230a 0x25117 0x230a0002 0x5118230a 0x25119 0x230a0002 0x511a230a 0x2511b 0x230a0002 0x511c230a 0x2511d 0x230a0002 0x511e230a 0x2511f 0x230a0002 0x5120230a 0x25121 0x230a0002 0x5122230a 0x25123 0x230a0002 0x5124230a 0x25125 0x230a0002 0x5126230a 0x25127 0x230a0002 0x5128230a 0x25129 0x230a0002 0x512a230a 0x2512b 0x230a0002 0x512c230a 0x2512d 0x230a0002 0x512e230a 0x2512f 0x230a0002 0x5130230a 0x25131 0x230a0002 0x5132230a 0x25133 0x230a0002 0x5134230a 0x25135 0x230a0002 0x5136230a 0x25137 0x230a0002 0x5138230a 0x25139 0x230a0002 0x513a230a 0x2513b 0x230a0002 0x513c230a 0x2513d 0x230a0002 0x513e230a 0x2513f 0x230a0002 0x5140230a 0x25141 0x230a0002 0x5142230a 0x25143 0x230a0002 0x5144230a 0x25145 0x230a0002 0x5146230a 0x25147 0x230a0002 0x5148230a 0x25149 0x230a0002 0x514a230a 0x2514b 0x230a0002 0x514c230a 0x2514d 0x230a0002 0x514e230a 0x2514f 0x230a0002 0x5150230a 0x25151 0x230a0002 0x5152230a 0x25153 0x230a0002 0x5154230a 0x25155 0x230a0002 0x5156230a 0x25157 0x230a0002 0x5158230a 0x25159 0x230a0002 0x515a230a 0x2515b 0x230a0002 0x515c230a 0x2515d 0x230a0002 0x515e230a 0x2515f 0x230a0002 0x5160230a 0x25161 0x230a0002 0x5162230a 0x25163 0x230a0002 0x5164230a 0x25165 0x230a0002 0x5166230a 0x25167 0x230a0002 0x5168230a 0x25169 0x230a0002 0x516a230a 0x2516b 0x230a0002 0x516c230a 0x2516d 0x230a0002 0x516e230a 0x2516f 0x230a0002 0x5170230a 0x25171 0x230a0002 0x5172230a 0x25173 0x230a0002 0x5174230a 0x25175 0x230a0002 0x5176230a 0x25177 0x230a0002 0x5178230a 0x25179 0x230a0002 0x517a230a 0x2517b 0x230a0002 0x517c230a 0x2517d 0x230a0002 0x517e230a 0x2517f 0x230a0002 0x5180230a 0x25181 0x230a0002 0x5182230a 0x25183 0x230a0002 0x5184230a 0x25185 0x230a0002 0x5186230a 0x25187 0x230a0002 0x5188230a 0x25189 0x230a0002 0x518a230a 0x2518b 0x230a0002 0x518c230a 0x2518d 0x230a0002 0x518e230a 0x2518f 0x230a0002 0x5190230a 0x25191 0x230a0002 0x5192230a 0x25193 0x230a0002 0x5194230a 0x25195 0x230a0002 0x5196230a 0x25197 0x230a0002 0x5198230a 0x25199 0x230a0002 0x519a230a 0x2519b 0x230a0002 0x519c230a 0x2519d 0x230a0002 0x519e230a 0x2519f 0x230a0002 0x51a0230a 0x251a1 0x230a0002 0x51a2230a 0x251a3 0x230a0002 0x51a4230a 0x251a5 0x230a0002 0x51a6230a 0x251a7 0x230a0002 0x51a8230a 0x251a9 0x230a0002 0x51aa230a 0x251ab 0x230a0002 0x51ac230a 0x251ad 0x230a0002 0x51ae230a 0x251af 0x230a0002 0x51b0230a 0x251b1 0x230a0002 0x51b2230a 0x251b3 0x230a0002 0x51b4230a 0x251b5 0x230a0002 0x51b6230a 0x251b7 0x230a0002 0x51b8230a 0x251b9 0x230a0002 0x51ba230a 0x251bb 0x230a0002 0x51bc230a 0x251bd 0x230a0002 0x51be230a 0x251bf 0x230a0002 0x51c0230a 0x251c1 0x230a0002 0x51c2230a 0x251c3 0x230a0002 0x51c4230a 0x251c5 0x230a0002 0x51c6230a 0x251c7 0x230a0002 0x51c8230a 0x251c9 0x230a0002 0x51ca230a 0x251cb 0x230a0002 0x51cc230a 0x251cd 0x230a0002 0x51ce230a 0x251cf 0x230a0002 0x51d0230a 0x251d1 0x230a0002 0x51d2230a 0x251d3 0x230a0002 0x51d4230a 0x251d5 0x230a0002 0x51d6230a 0x251d7 0x230a0002 0x51d8230a 0x251d9 0x230a0002 0x51da230a 0x251db 0x230a0002 0x51dc230a 0x251dd 0x230a0002 0x51de230a 0x251df 0x230a0002 0x51e0230a 0x251e1 0x230a0002 0x51e2230a 0x251e3 0x230a0002 0x51e4230a 0x251e5 0x230a0002 0x51e6230a 0x251e7 0x230a0002 0x51e8230a 0x251e9 0x230a0002 0x51ea230a 0x251eb 0x230a0002 0x51ec230a 0x251ed 0x230a0002 0x51ee230a 0x251ef 0x230a0002 0x51f0230a 0x251f1 0x230a0002 0x51f2230a 0x251f3 0x230a0002 0x51f4230a 0x251f5 0x230a0002 0x51f6230a 0x251f7 0x230a0002 0x51f8230a 0x251f9 0x230a0002 0x51fa230a 0x251fb 0x230a0002 0x51fc230a 0x251fd 0x230a0002 0x51fe230a 0x251ff>;
		};
	};

	mt108_lcd86011508: lcd86011508@86011508 {
		work-mode = <0x00>;
		bpp = <0x18>;
		lane-number = <0x01>;
		non-continue-clk-en = <0x01>;
		need-check-esd = <0x03>;
		esd-timeout = <0x7d0>;
		esd-check-reg = <0x0a>;
		esd-return-code = <0x9c>;
		fps = <0x3c>;
		width-mm = <0x44>;
		height-mm = <0x79>;
		panel-name = "lcd_sh8601z_oled1508_mipi";
		power-on-sequence = <0x21 0x01 0x14 0x32 0x01 0x14 0x32 0x00 0x32 0x32 0x01 0x78>;
		power-off-sequence = <0x32 0x00 0x14 0x21 0x00 0x14>;
		init-data = [29 00 00 03 c0 5a 5a 29 00 00 03 c1 5a 5a 23 00 00 02 e4 01 23 00 00 02 b0 31 23 00 00 02 b2 18 23 00 00 02 b0 06 23 00 00 02 e7 00 13 78 00 01 11 29 00 00 03 c0 5a 5a 29 00 00 03 c1 5a 5a 23 00 00 02 b0 04 29 00 00 03 b1 d4 01 23 00 00 02 b0 02 29 00 00 03 d3 d4 01 29 00 00 05 2a 00 00 01 d3 29 00 00 05 2b 00 00 01 d1 29 00 00 03 44 00 bc 23 00 00 02 35 00 23 00 00 02 3a 77 23 00 00 02 51 00 23 78 00 02 53 20 13 32 00 01 29];
		aod-in = [05 0a 00 01 39];
		aod-out = [05 0a 00 01 38];
		sleep-in = [13 0a 00 01 28 13 78 00 01 10];
		sleep-out = [13 78 00 01 11 13 32 00 01 29];

		display-timings {
			clock-frequency = <0x63da8>;
			hactive = <0x1d4>;
			vactive = <0x1d2>;
			hback-porch = <0x08>;
			hfront-porch = <0x0c>;
			hsync-len = <0x02>;
			vfront-porch = <0x08>;
			vback-porch = <0x07>;
			vsync-len = <0x01>;
		};

		oled-backlight {
			default-brightness = <0x19>;
			max-level = <0xff>;
			brightness-levels = <0x230a0002 0x5100230a 0x25101 0x230a0002 0x5102230a 0x25103 0x230a0002 0x5104230a 0x25105 0x230a0002 0x5106230a 0x25107 0x230a0002 0x5108230a 0x25109 0x230a0002 0x510a230a 0x2510b 0x230a0002 0x510c230a 0x2510d 0x230a0002 0x510e230a 0x2510f 0x230a0002 0x5110230a 0x25111 0x230a0002 0x5112230a 0x25113 0x230a0002 0x5114230a 0x25115 0x230a0002 0x5116230a 0x25117 0x230a0002 0x5118230a 0x25119 0x230a0002 0x511a230a 0x2511b 0x230a0002 0x511c230a 0x2511d 0x230a0002 0x511e230a 0x2511f 0x230a0002 0x5120230a 0x25121 0x230a0002 0x5122230a 0x25123 0x230a0002 0x5124230a 0x25125 0x230a0002 0x5126230a 0x25127 0x230a0002 0x5128230a 0x25129 0x230a0002 0x512a230a 0x2512b 0x230a0002 0x512c230a 0x2512d 0x230a0002 0x512e230a 0x2512f 0x230a0002 0x5130230a 0x25131 0x230a0002 0x5132230a 0x25133 0x230a0002 0x5134230a 0x25135 0x230a0002 0x5136230a 0x25137 0x230a0002 0x5138230a 0x25139 0x230a0002 0x513a230a 0x2513b 0x230a0002 0x513c230a 0x2513d 0x230a0002 0x513e230a 0x2513f 0x230a0002 0x5140230a 0x25141 0x230a0002 0x5142230a 0x25143 0x230a0002 0x5144230a 0x25145 0x230a0002 0x5146230a 0x25147 0x230a0002 0x5148230a 0x25149 0x230a0002 0x514a230a 0x2514b 0x230a0002 0x514c230a 0x2514d 0x230a0002 0x514e230a 0x2514f 0x230a0002 0x5150230a 0x25151 0x230a0002 0x5152230a 0x25153 0x230a0002 0x5154230a 0x25155 0x230a0002 0x5156230a 0x25157 0x230a0002 0x5158230a 0x25159 0x230a0002 0x515a230a 0x2515b 0x230a0002 0x515c230a 0x2515d 0x230a0002 0x515e230a 0x2515f 0x230a0002 0x5160230a 0x25161 0x230a0002 0x5162230a 0x25163 0x230a0002 0x5164230a 0x25165 0x230a0002 0x5166230a 0x25167 0x230a0002 0x5168230a 0x25169 0x230a0002 0x516a230a 0x2516b 0x230a0002 0x516c230a 0x2516d 0x230a0002 0x516e230a 0x2516f 0x230a0002 0x5170230a 0x25171 0x230a0002 0x5172230a 0x25173 0x230a0002 0x5174230a 0x25175 0x230a0002 0x5176230a 0x25177 0x230a0002 0x5178230a 0x25179 0x230a0002 0x517a230a 0x2517b 0x230a0002 0x517c230a 0x2517d 0x230a0002 0x517e230a 0x2517f 0x230a0002 0x5180230a 0x25181 0x230a0002 0x5182230a 0x25183 0x230a0002 0x5184230a 0x25185 0x230a0002 0x5186230a 0x25187 0x230a0002 0x5188230a 0x25189 0x230a0002 0x518a230a 0x2518b 0x230a0002 0x518c230a 0x2518d 0x230a0002 0x518e230a 0x2518f 0x230a0002 0x5190230a 0x25191 0x230a0002 0x5192230a 0x25193 0x230a0002 0x5194230a 0x25195 0x230a0002 0x5196230a 0x25197 0x230a0002 0x5198230a 0x25199 0x230a0002 0x519a230a 0x2519b 0x230a0002 0x519c230a 0x2519d 0x230a0002 0x519e230a 0x2519f 0x230a0002 0x51a0230a 0x251a1 0x230a0002 0x51a2230a 0x251a3 0x230a0002 0x51a4230a 0x251a5 0x230a0002 0x51a6230a 0x251a7 0x230a0002 0x51a8230a 0x251a9 0x230a0002 0x51aa230a 0x251ab 0x230a0002 0x51ac230a 0x251ad 0x230a0002 0x51ae230a 0x251af 0x230a0002 0x51b0230a 0x251b1 0x230a0002 0x51b2230a 0x251b3 0x230a0002 0x51b4230a 0x251b5 0x230a0002 0x51b6230a 0x251b7 0x230a0002 0x51b8230a 0x251b9 0x230a0002 0x51ba230a 0x251bb 0x230a0002 0x51bc230a 0x251bd 0x230a0002 0x51be230a 0x251bf 0x230a0002 0x51c0230a 0x251c1 0x230a0002 0x51c2230a 0x251c3 0x230a0002 0x51c4230a 0x251c5 0x230a0002 0x51c6230a 0x251c7 0x230a0002 0x51c8230a 0x251c9 0x230a0002 0x51ca230a 0x251cb 0x230a0002 0x51cc230a 0x251cd 0x230a0002 0x51ce230a 0x251cf 0x230a0002 0x51d0230a 0x251d1 0x230a0002 0x51d2230a 0x251d3 0x230a0002 0x51d4230a 0x251d5 0x230a0002 0x51d6230a 0x251d7 0x230a0002 0x51d8230a 0x251d9 0x230a0002 0x51da230a 0x251db 0x230a0002 0x51dc230a 0x251dd 0x230a0002 0x51de230a 0x251df 0x230a0002 0x51e0230a 0x251e1 0x230a0002 0x51e2230a 0x251e3 0x230a0002 0x51e4230a 0x251e5 0x230a0002 0x51e6230a 0x251e7 0x230a0002 0x51e8230a 0x251e9 0x230a0002 0x51ea230a 0x251eb 0x230a0002 0x51ec230a 0x251ed 0x230a0002 0x51ee230a 0x251ef 0x230a0002 0x51f0230a 0x251f1 0x230a0002 0x51f2230a 0x251f3 0x230a0002 0x51f4230a 0x251f5 0x230a0002 0x51f6230a 0x251f7 0x230a0002 0x51f8230a 0x251f9 0x230a0002 0x51fa230a 0x251fb 0x230a0002 0x51fc230a 0x251fd 0x230a0002 0x51fe230a 0x251ff>;
		};
	};

	mt108_lcd77916150: lcd77916150@77916150 {
		work-mode = <0x01>;
		bpp = <0x12>;
		lane-number = <0x01>;
		hsync-pol = <0x00>;
		vsync-pol = <0x00>;
		de-pol = <0x00>;
		te-pol = <0x00>;
		color-mode-pol = <0x01>;
		shut-down-pol = <0x01>;
		need-check-esd = <0x00>;
		esd-timeout = <0x3e8>;
		fps = <0x32>;
		panel-name = "lcd_st77916_mipi_cto150";
		power-on-sequence = <0x32 0x01 0x32 0x32 0x00 0x32 0x32 0x01 0x78>;
		power-off-sequence = <0x32 0x00 0x14>;
		init-data = [29 00 00 03 f0 00 08 29 00 00 03 f2 00 08 29 00 00 03 9b 00 51 29 00 00 03 86 00 53 29 00 00 03 f2 00 80 29 00 00 03 f0 00 00 29 00 00 03 f0 00 28 29 00 00 03 f2 00 28 29 00 00 03 83 00 e8 29 00 00 03 84 00 69 29 00 00 03 f2 00 82 29 00 00 03 f0 00 00 29 00 00 03 f0 00 01 29 00 00 03 f1 00 01 29 00 00 03 b0 00 52 29 00 00 03 b1 00 51 29 00 00 03 b2 00 20 29 00 00 03 b4 00 84 29 00 00 03 b5 00 44 29 00 00 03 b6 00 8b 29 00 00 03 b7 00 40 29 00 00 03 b8 00 05 29 00 00 03 ba 00 00 29 00 00 03 bb 00 08 29 00 00 03 bc 00 08 29 00 00 03 bd 00 00 29 00 00 03 c0 00 80 29 00 00 03 c1 00 0c 29 00 00 03 c2 00 38 29 00 00 03 c3 00 80 29 00 00 03 c4 00 0c 29 00 00 03 c5 00 38 29 00 00 03 c6 00 a9 29 00 00 03 c7 00 41 29 00 00 03 c8 00 51 29 00 00 03 c9 00 a9 29 00 00 03 ca 00 41 29 00 00 03 cb 00 51 29 00 00 03 d0 00 91 29 00 00 03 d1 00 68 29 00 00 03 d2 00 69 29 00 00 04 f5 00 00 a5 29 00 00 03 dd 00 4b 29 00 00 03 de 00 4b 29 00 00 03 f1 00 10 29 00 00 03 f0 00 00 29 00 00 03 f0 00 02 29 05 00 1d e0 00 f0 00 0a 00 11 00 0b 00 0b 00 07 00 3c 00 44 00 52 00 09 00 16 00 15 00 31 00 34 29 05 00 1d e1 00 f0 00 0a 00 11 00 0b 00 0b 00 07 00 3b 00 43 00 4f 00 08 00 15 00 15 00 2e 00 34 29 00 00 03 f0 00 10 29 00 00 03 f3 00 10 29 00 00 03 e0 00 08 29 00 00 03 e1 00 00 29 00 00 03 e2 00 0c 29 00 00 03 e3 00 00 29 00 00 03 e4 00 e0 29 00 00 03 e5 00 06 29 00 00 03 e6 00 21 29 00 00 03 e7 00 10 29 00 00 03 e8 00 8a 29 00 00 03 e9 00 82 29 00 00 03 ea 00 e4 29 00 00 03 eb 00 00 29 00 00 03 ec 00 00 29 00 00 03 ed 00 14 29 00 00 03 ee 00 ff 29 00 00 03 ef 00 00 29 00 00 03 f8 00 ff 29 00 00 03 f9 00 00 29 00 00 03 fa 00 00 29 00 00 03 fb 00 30 29 00 00 03 fc 00 00 29 00 00 03 fd 00 00 29 00 00 03 fe 00 00 29 00 00 03 ff 00 00 29 00 00 03 60 00 50 29 00 00 03 61 00 02 29 00 00 03 62 00 0c 29 00 00 03 63 00 50 29 00 00 03 64 00 04 29 00 00 03 65 00 0c 29 00 00 03 66 00 52 29 00 00 03 67 00 d6 29 00 00 03 68 00 0c 29 00 00 03 69 00 52 29 00 00 03 6a 00 d8 29 00 00 03 6b 00 0c 29 00 00 03 70 00 50 29 00 00 03 71 00 01 29 00 00 03 72 00 0c 29 00 00 03 73 00 50 29 00 00 03 74 00 03 29 00 00 03 75 00 0c 29 00 00 03 76 00 52 29 00 00 03 77 00 d5 29 00 00 03 78 00 0c 29 00 00 03 79 00 52 29 00 00 03 7a 00 d7 29 00 00 03 7b 00 0c 29 00 00 03 80 00 58 29 00 00 03 81 00 00 29 00 00 03 82 00 04 29 00 00 03 83 00 02 29 00 00 03 84 00 dc 29 00 00 03 85 00 00 29 00 00 03 86 00 00 29 00 00 03 87 00 00 29 00 00 03 88 00 58 29 00 00 03 89 00 00 29 00 00 03 8a 00 06 29 00 00 03 8b 00 02 29 00 00 03 8c 00 de 29 00 00 03 8d 00 00 29 00 00 03 8e 00 00 29 00 00 03 8f 00 00 29 00 00 03 90 00 58 29 00 00 03 91 00 00 29 00 00 03 92 00 08 29 00 00 03 93 00 02 29 00 00 03 94 00 e0 29 00 00 03 95 00 00 29 00 00 03 96 00 00 29 00 00 03 97 00 00 29 00 00 03 98 00 58 29 00 00 03 99 00 00 29 00 00 03 9a 00 0a 29 00 00 03 9b 00 02 29 00 00 03 9c 00 e2 29 00 00 03 9d 00 00 29 00 00 03 9e 00 00 29 00 00 03 9f 00 00 29 00 00 03 a0 00 58 29 00 00 03 a1 00 00 29 00 00 03 a2 00 03 29 00 00 03 a3 00 02 29 00 00 03 a4 00 db 29 00 00 03 a5 00 00 29 00 00 03 a6 00 00 29 00 00 03 a7 00 00 29 00 00 03 a8 00 58 29 00 00 03 a9 00 00 29 00 00 03 aa 00 05 29 00 00 03 ab 00 02 29 00 00 03 ac 00 dd 29 00 00 03 ad 00 00 29 00 00 03 ae 00 00 29 00 00 03 af 00 00 29 00 00 03 b0 00 58 29 00 00 03 b1 00 00 29 00 00 03 b2 00 07 29 00 00 03 b3 00 02 29 00 00 03 b4 00 df 29 00 00 03 b5 00 00 29 00 00 03 b6 00 00 29 00 00 03 b7 00 00 29 00 00 03 b8 00 58 29 00 00 03 b9 00 00 29 00 00 03 ba 00 09 29 00 00 03 bb 00 02 29 00 00 03 bc 00 e1 29 00 00 03 bd 00 00 29 00 00 03 be 00 00 29 00 00 03 bf 00 00 29 00 00 03 c0 00 77 29 00 00 03 c1 00 46 29 00 00 03 c2 00 55 29 00 00 03 c3 00 64 29 00 00 03 c4 00 bb 29 00 00 03 c5 00 21 29 00 00 03 c6 00 30 29 00 00 03 c7 00 aa 29 00 00 03 c8 00 12 29 00 00 03 c9 00 03 29 00 00 03 d0 00 77 29 00 00 03 d1 00 46 29 00 00 03 d2 00 55 29 00 00 03 d3 00 64 29 00 00 03 d4 00 bb 29 00 00 03 d5 00 21 29 00 00 03 d6 00 30 29 00 00 03 d7 00 aa 29 00 00 03 d8 00 12 29 00 00 03 d9 00 03 29 00 00 03 f3 00 01 29 00 00 03 f0 00 00 29 00 00 03 f0 00 01 29 00 00 03 f1 00 01 29 00 00 03 a0 00 0b 29 00 00 03 a3 00 2a 29 00 00 03 a5 00 c3 29 00 00 03 a3 00 2b 29 00 00 03 a5 00 c3 29 00 00 03 a3 00 2c 29 00 00 03 a5 00 c3 29 00 00 03 a3 00 2d 29 00 00 03 a5 00 c3 29 00 00 03 a3 00 2e 29 00 00 03 a5 00 c3 29 00 00 03 a3 00 2f 29 00 00 03 a5 00 c3 29 00 00 03 a3 00 30 29 00 00 03 a5 00 c3 29 00 00 03 a3 00 31 29 00 00 03 a5 00 c3 29 00 00 03 a3 00 32 29 00 00 03 a5 00 c3 29 00 00 03 a3 00 33 29 00 00 03 a5 00 c3 29 00 00 03 a0 00 09 29 00 00 03 f1 00 10 29 00 00 03 f0 00 00 29 00 00 09 2a 00 00 00 00 00 01 00 67 29 00 00 09 2b 00 01 00 68 00 01 00 68 29 00 00 03 4d 00 00 29 00 00 03 4e 00 00 29 00 00 03 4f 00 00 29 00 00 03 4c 00 01 29 00 00 03 4c 00 00 29 00 00 09 2a 00 00 00 00 00 01 00 67 29 00 00 09 2b 00 00 00 00 00 01 00 67 13 00 00 01 21 29 00 00 03 3a 00 66 13 00 00 01 35 13 78 00 01 11 13 00 00 01 29 13 1a 00 01 00];
		sleep-in = [13 0a 00 01 28 13 78 00 01 10];
		sleep-out = [13 78 00 01 11 13 64 00 01 29];

		display-timings {
			clock-frequency = <0x53020>;
			hactive = <0x168>;
			vactive = <0x168>;
			hback-porch = <0x3c>;
			hfront-porch = <0x50>;
			vback-porch = <0x08>;
			vfront-porch = <0x08>;
			hsync-len = <0x10>;
			vsync-len = <0x02>;
		};
	};

	mt108_lcd77916185: lcd77916185@77916185 {
		work-mode = <0x00>;
		bpp = <0x12>;
		lane-number = <0x01>;
		hsync-pol = <0x00>;
		vsync-pol = <0x00>;
		de-pol = <0x00>;
		te-pol = <0x00>;
		color-mode-pol = <0x01>;
		shut-down-pol = <0x01>;
		need-check-esd = <0x00>;
		esd-timeout = <0x3e8>;
		fps = <0x3c>;
		panel-name = "lcd_st77916_mipi_hsd185";
		power-on-sequence = <0x32 0x01 0x14 0x32 0x00 0x14 0x32 0x01 0x32>;
		power-off-sequence = <0x32 0x00 0x14>;
		init-data = [29 00 00 03 f0 00 28 29 00 00 03 f2 00 28 29 00 00 03 7c 00 d1 29 00 00 03 83 00 e0 29 00 00 03 84 00 61 29 00 00 03 f2 00 82 29 00 00 03 f0 00 00 29 00 00 03 f0 00 01 29 00 00 03 f1 00 01 29 00 00 03 b0 00 39 29 00 00 03 b1 00 3a 29 00 00 03 b2 00 1f 29 00 00 03 b4 00 46 29 00 00 03 b5 00 34 29 00 00 03 b6 00 d5 29 00 00 03 b7 00 30 29 00 00 03 b8 00 04 29 00 00 03 ba 00 00 29 00 00 03 bb 00 08 29 00 00 03 bc 00 08 29 00 00 03 bd 00 00 29 00 00 03 c0 00 80 29 00 00 03 c1 00 10 29 00 00 03 c2 00 37 29 00 00 03 c3 00 80 29 00 00 03 c4 00 10 29 00 00 03 c5 00 37 29 00 00 03 c6 00 a9 29 00 00 03 c7 00 41 29 00 00 03 c8 00 01 29 00 00 03 c9 00 a9 29 00 00 03 ca 00 41 29 00 00 03 cb 00 01 29 00 00 03 d0 00 91 29 00 00 03 d1 00 68 29 00 00 03 d2 00 68 29 00 00 05 f5 00 00 00 a5 29 00 00 03 f1 00 10 29 00 00 03 f0 00 00 29 00 00 03 f0 00 02 29 05 00 1d e0 00 70 00 09 00 12 00 0c 00 0b 00 27 00 38 00 54 00 4e 00 19 00 15 00 15 00 2c 00 2f 29 05 00 1d e1 00 70 00 08 00 11 00 0c 00 0b 00 27 00 38 00 43 00 4c 00 18 00 14 00 14 00 2b 00 2d 29 00 00 03 f0 00 10 29 00 00 03 f3 00 10 29 00 00 03 e0 00 08 29 00 00 03 e1 00 00 29 00 00 03 e2 00 0b 29 00 00 03 e3 00 00 29 00 00 03 e4 00 e0 29 00 00 03 e5 00 06 29 00 00 03 e6 00 21 29 00 00 03 e7 00 00 29 00 00 03 e8 00 05 29 00 00 03 e9 00 82 29 00 00 03 ea 00 df 29 00 00 03 eb 00 89 29 00 00 03 ec 00 20 29 00 00 03 ed 00 14 29 00 00 03 ee 00 ff 29 00 00 03 ef 00 00 29 00 00 03 f8 00 ff 29 00 00 03 f9 00 00 29 00 00 03 fa 00 00 29 00 00 03 fb 00 30 29 00 00 03 fc 00 00 29 00 00 03 fd 00 00 29 00 00 03 fe 00 00 29 00 00 03 ff 00 00 29 00 00 03 60 00 42 29 00 00 03 61 00 e0 29 00 00 03 62 00 40 29 00 00 03 63 00 40 29 00 00 03 64 00 02 29 00 00 03 65 00 00 29 00 00 03 66 00 40 29 00 00 03 67 00 03 29 00 00 03 68 00 00 29 00 00 03 69 00 00 29 00 00 03 6a 00 00 29 00 00 03 6b 00 00 29 00 00 03 70 00 42 29 00 00 03 71 00 e0 29 00 00 03 72 00 40 29 00 00 03 73 00 40 29 00 00 03 74 00 02 29 00 00 03 75 00 00 29 00 00 03 76 00 40 29 00 00 03 77 00 03 29 00 00 03 78 00 00 29 00 00 03 79 00 00 29 00 00 03 7a 00 00 29 00 00 03 7b 00 00 29 00 00 03 80 00 38 29 00 00 03 81 00 00 29 00 00 03 82 00 04 29 00 00 03 83 00 02 29 00 00 03 84 00 dc 29 00 00 03 85 00 00 29 00 00 03 86 00 00 29 00 00 03 87 00 00 29 00 00 03 88 00 38 29 00 00 03 89 00 00 29 00 00 03 8a 00 06 29 00 00 03 8b 00 02 29 00 00 03 8c 00 de 29 00 00 03 8d 00 00 29 00 00 03 8e 00 00 29 00 00 03 8f 00 00 29 00 00 03 90 00 38 29 00 00 03 91 00 00 29 00 00 03 92 00 08 29 00 00 03 93 00 02 29 00 00 03 94 00 e0 29 00 00 03 95 00 00 29 00 00 03 96 00 00 29 00 00 03 97 00 00 29 00 00 03 98 00 38 29 00 00 03 99 00 00 29 00 00 03 9a 00 0a 29 00 00 03 9b 00 02 29 00 00 03 9c 00 e2 29 00 00 03 9d 00 00 29 00 00 03 9e 00 00 29 00 00 03 9f 00 00 29 00 00 03 a0 00 38 29 00 00 03 a1 00 00 29 00 00 03 a2 00 03 29 00 00 03 a3 00 02 29 00 00 03 a4 00 db 29 00 00 03 a5 00 00 29 00 00 03 a6 00 00 29 00 00 03 a7 00 00 29 00 00 03 a8 00 38 29 00 00 03 a9 00 00 29 00 00 03 aa 00 05 29 00 00 03 ab 00 02 29 00 00 03 ac 00 dd 29 00 00 03 ad 00 00 29 00 00 03 ae 00 00 29 00 00 03 af 00 00 29 00 00 03 b0 00 38 29 00 00 03 b1 00 00 29 00 00 03 b2 00 07 29 00 00 03 b3 00 02 29 00 00 03 b4 00 df 29 00 00 03 b5 00 00 29 00 00 03 b6 00 00 29 00 00 03 b7 00 00 29 00 00 03 b8 00 38 29 00 00 03 b9 00 00 29 00 00 03 ba 00 09 29 00 00 03 bb 00 02 29 00 00 03 bc 00 e1 29 00 00 03 bd 00 00 29 00 00 03 be 00 00 29 00 00 03 bf 00 00 29 00 00 03 c0 00 22 29 00 00 03 c1 00 aa 29 00 00 03 c2 00 65 29 00 00 03 c3 00 74 29 00 00 03 c4 00 47 29 00 00 03 c5 00 56 29 00 00 03 c6 00 00 29 00 00 03 c7 00 88 29 00 00 03 c8 00 99 29 00 00 03 c9 00 33 29 00 00 03 d0 00 11 29 00 00 03 d1 00 aa 29 00 00 03 d2 00 65 29 00 00 03 d3 00 74 29 00 00 03 d4 00 47 29 00 00 03 d5 00 56 29 00 00 03 d6 00 00 29 00 00 03 d7 00 88 29 00 00 03 d8 00 99 29 00 00 03 d9 00 33 29 00 00 03 f3 00 01 29 00 00 03 f0 00 00 13 00 00 01 21 13 00 00 01 35 13 48 00 01 11 13 00 00 01 29 13 05 00 01 00];
		sleep-in = [13 0a 00 01 28 13 78 00 01 10];
		sleep-out = [13 78 00 01 11 13 64 00 01 29];

		display-timings {
			clock-frequency = <0x518b0>;
			hactive = <0x168>;
			vactive = <0x168>;
			hback-porch = <0x3c>;
			hfront-porch = <0x50>;
			vback-porch = <0x08>;
			vfront-porch = <0x08>;
			hsync-len = <0x10>;
			vsync-len = <0x02>;
		};
	};

	mt108_lcd9855180: lcd9855180@9855180 {
		work-mode = <0x00>;
		bpp = <0x12>;
		lane-number = <0x01>;
		hsync-pol = <0x00>;
		vsync-pol = <0x00>;
		de-pol = <0x00>;
		te-pol = <0x00>;
		color-mode-pol = <0x01>;
		shut-down-pol = <0x01>;
		need-check-esd = <0x00>;
		esd-timeout = <0x3e8>;
		fps = <0x3c>;
		panel-name = "lcd_jd9855_mipi_boe180";
		power-on-sequence = <0x32 0x01 0x32 0x32 0x00 0x32 0x32 0x01 0x78>;
		power-off-sequence = <0x32 0x00 0x14>;
		init-data = <0x23000002 0xde002900 0x3df98 0x55230000 0x2b21f29 0x5b7 0x12d0155 0x29000007 0xbb1b64c4 0xe3ef529 0x5bc 0x320f3c0 0x29000003 0xc022a129 0xcc3 0x22a0b 0x8480804 0x62303029 0xcc4 0x4000ad68 0x43070416 0x43070429 0x50021c8 0x3f312825 0x25272222 0x201f1c12 0xf0b0202 0x3f312825 0x25272222 0x201f1c12 0xf0b0202 0x29000003 0xd3281329 0x7d9 0xff00 0xf0002300 0x2de01 0x29000009 0xb713e764 0x39063619 0x1c230000 0x2be0029 0x4c1 0x4a8029 0x5c2 0x16dae7 0x29000009 0xc7000000 0x38080800 0x1290000 0x7c80000 0x153b 0x29000006 0xc9001606 0x40a2900 0x6ca08 0x35161f1f 0x29000006 0xcb011607 0x50b2900 0x6cc09 0x35161f1f 0x29000006 0xcd011609 0xb052900 0x6ce07 0x151f161f 0x29000006 0xcf001608 0xa042900 0x6d006 0x151f161f 0x29000003 0xd1023029 0x6d2 0x20352df 0xdd290000 0x4d33b04 0x48290000 0x8d51010 0x7070f94 0x26290000 0x4d60000 0x40290000 0x4d70000 0x20230000 0x2de0223 0x2b6 0x1c230000 0x2de0023 0x24d 0x230000 0x24e0023 0x24f 0x230a00 0x24c0123 0x24c 0x290000 0x52a0000 0x1672900 0x52b00 0x16713 0x135 0x23000002 0x3a661378 0x11113 0xa000129>;
		sleep-in = [13 0a 00 01 28 13 78 00 01 10];
		sleep-out = [13 78 00 01 11 13 64 00 01 29];

		display-timings {
			clock-frequency = <0x518b0>;
			hactive = <0x168>;
			vactive = <0x168>;
			hback-porch = <0x3c>;
			hfront-porch = <0x50>;
			vback-porch = <0x08>;
			vfront-porch = <0x08>;
			hsync-len = <0x10>;
			vsync-len = <0x02>;
		};
	};

	mt108_lcd9855: lcd9855@9855 {
		work-mode = <0x00>;
		bpp = <0x12>;
		lane-number = <0x01>;
		hsync-pol = <0x00>;
		vsync-pol = <0x00>;
		de-pol = <0x00>;
		te-pol = <0x00>;
		color-mode-pol = <0x01>;
		shut-down-pol = <0x01>;
		need-check-esd = <0x00>;
		esd-timeout = <0x3e8>;
		fps = <0x3c>;
		panel-name = "lcd_jd9855_mipi";
		power-on-sequence = <0x32 0x01 0x32 0x32 0x00 0x32 0x32 0x01 0x78>;
		power-off-sequence = <0x32 0x00 0x14>;
		init-data = [23 00 00 02 de 00 29 00 00 03 df 98 55 29 00 00 03 ce 0d 00 23 00 00 02 b2 30 29 00 00 05 b7 01 35 01 5d 29 00 00 07 bb 1b 64 e3 34 3e f3 29 00 00 05 bc 00 18 f3 c0 29 00 00 03 c0 22 c1 29 00 00 0c c3 00 02 2a 0b 08 47 08 04 62 30 30 29 00 00 0c c4 40 00 ad 68 43 07 04 16 43 07 04 29 05 00 21 c8 3f 2e 24 1f 20 21 1d 1d 1d 1c 19 0e 0b 07 03 02 3f 2e 24 1f 20 21 1d 1d 1d 1c 19 0e 0b 07 03 02 29 00 00 03 d3 28 13 29 00 00 03 d7 18 30 29 00 00 07 d9 00 00 ff 00 f0 00 23 00 00 02 de 01 29 00 00 09 b7 13 e7 64 39 06 36 19 1c 23 00 00 02 be 00 29 00 00 05 c1 04 4a 90 08 29 00 00 05 c2 00 16 da e7 29 00 00 03 c4 72 12 29 00 00 07 c7 00 00 09 3d 09 3d 29 00 00 07 c8 00 00 0b 3d 16 39 29 00 00 06 c9 00 0a 08 06 04 29 00 00 06 ca 1e 1f 10 17 18 29 00 00 06 cb 01 0b 09 07 05 29 00 00 06 cc 1e 1f 11 17 18 29 00 00 06 cd 31 25 27 29 2b 29 00 00 06 ce 3f 3e 21 37 38 29 00 00 06 cf 30 24 26 28 2a 29 00 00 06 d0 3f 3e 20 37 38 29 00 00 06 d1 06 30 a5 db 30 29 00 00 07 d3 3b 08 00 00 00 00 29 00 00 07 d4 67 00 00 01 00 01 29 00 00 08 d5 10 10 07 07 0f 94 26 29 00 00 04 d6 00 00 40 29 00 00 04 d7 01 84 20 23 00 00 02 de 02 23 00 00 02 b6 1c 23 00 00 02 de 00 23 00 00 02 4d 00 23 00 00 02 4e 00 23 00 00 02 4f 00 23 0a 00 02 4c 01 23 00 00 02 4c 00 29 00 00 05 2a 00 00 01 68 29 00 00 05 2b 00 00 01 68 13 00 00 01 35 23 00 00 02 36 00 23 00 00 02 3a 66 13 78 00 01 11 13 0a 00 01 29];
		sleep-in = [13 0a 00 01 28 13 78 00 01 10];
		sleep-out = [13 78 00 01 11 13 64 00 01 29];

		display-timings {
			clock-frequency = <0x518b0>;
			hactive = <0x168>;
			vactive = <0x168>;
			hback-porch = <0x3c>;
			hfront-porch = <0x50>;
			vback-porch = <0x08>;
			vfront-porch = <0x08>;
			hsync-len = <0x10>;
			vsync-len = <0x02>;
		};
	};

	mt108_lcd985522: lcd985522@985522 {
		work-mode = <0x00>;
		bpp = <0x12>;
		lane-number = <0x01>;
		hsync-pol = <0x00>;
		vsync-pol = <0x00>;
		de-pol = <0x00>;
		te-pol = <0x00>;
		color-mode-pol = <0x01>;
		shut-down-pol = <0x01>;
		need-check-esd = <0x00>;
		esd-timeout = <0x3e8>;
		fps = <0x3c>;
		panel-name = "lcd_jd9855_oled22_mipi";
		power-on-sequence = <0x32 0x01 0x32 0x32 0x00 0x32 0x32 0x01 0x78>;
		power-off-sequence = <0x32 0x00 0x14>;
		init-data = [23 00 00 02 de 00 29 00 00 03 df 98 55 23 00 00 02 b2 2e 29 00 00 05 b7 01 39 01 61 29 00 00 07 bb 1b 64 e4 36 3e f3 29 00 00 05 bc 00 18 f3 c0 29 00 00 03 c0 22 22 29 00 00 0c c3 00 02 23 0b 08 47 06 04 62 30 30 29 00 00 0c c4 40 00 ad 68 44 05 05 16 44 05 05 29 05 00 21 c8 3f 33 2a 27 28 2a 25 25 24 22 1e 11 0d 08 04 02 3f 33 2a 27 28 2a 25 25 24 22 1e 11 0d 08 04 02 29 00 00 03 d3 28 13 29 00 00 07 d9 00 00 ff 00 f0 00 23 00 00 02 de 01 29 00 00 09 b7 13 e7 64 39 06 36 18 18 23 00 00 02 be 00 29 00 00 05 c1 04 4a 90 08 29 00 00 04 c2 00 da e7 29 00 00 07 c7 00 00 0c 3c 0c 3c 29 00 00 07 c8 00 00 0b 3c 0c 3c 29 00 00 06 c9 00 0a 08 06 04 29 00 00 06 ca 1e 1f 10 17 18 29 00 00 06 cb 01 0b 09 07 05 29 00 00 06 cc 1e 1f 11 17 18 29 00 00 06 cd 31 25 27 29 2b 29 00 00 06 ce 3f 3e 21 37 38 29 00 00 06 cf 30 24 26 28 2a 29 00 00 06 d0 3f 3e 20 37 38 29 00 00 06 d1 08 30 a5 dd 30 29 00 00 07 d3 3b 0a 00 00 00 00 29 00 00 07 d4 67 00 00 01 00 01 29 00 00 08 d5 10 10 07 07 0f 94 26 29 00 00 04 d6 00 00 40 29 00 00 04 d7 03 8f 20 23 00 00 02 de 02 23 00 00 02 b6 1c 23 00 00 02 de 00 23 00 00 02 4d 00 23 00 00 02 4e 00 23 00 00 02 4f 00 23 0a 00 02 4c 01 23 00 00 02 4c 00 29 00 00 05 2a 00 00 01 67 29 00 00 05 2b 00 00 01 67 13 00 00 01 35 23 00 00 02 36 00 23 00 00 02 3a 66 23 00 00 02 de 01 23 00 00 02 e7 0e 23 00 00 02 de 02 29 00 00 03 ba 32 01 23 00 00 02 de 00 13 78 00 01 11 13 0a 00 01 29];
		sleep-in = [13 0a 00 01 28 13 78 00 01 10];
		sleep-out = [13 78 00 01 11 13 64 00 01 29];

		display-timings {
			clock-frequency = <0x518b0>;
			hactive = <0x168>;
			vactive = <0x168>;
			hback-porch = <0x3c>;
			hfront-porch = <0x50>;
			vback-porch = <0x08>;
			vfront-porch = <0x08>;
			hsync-len = <0x10>;
			vsync-len = <0x02>;
		};
	};

	mt108_lcd7802148: lcd7802148@7802148 {
		work-mode = <0x00>;
		bpp = <0x18>;
		lane-number = <0x01>;
		non-continue-clk-en = <0x00>;
		need-check-esd = <0x00>;
		esd-timeout = <0x7d0>;
		esd-check-reg = <0x0a>;
		esd-return-code = <0x9c>;
		fps = <0x3c>;
		width-mm = <0x44>;
		height-mm = <0x79>;
		panel-name = "lcd_st7802n_oled148_mipi";
		power-on-sequence = <0x21 0x01 0x14 0x32 0x01 0x14 0x32 0x00 0x14 0x32 0x01 0x32>;
		power-off-sequence = <0x32 0x00 0x14 0x21 0x00 0x14>;
		init-data = [13 78 00 01 11 23 00 00 02 53 20 23 00 00 02 51 00 23 00 00 02 3a 77 23 00 00 02 35 00 13 64 00 01 29];
		aod-in = [13 0a 00 01 39];
		aod-out = [13 0a 00 01 38];
		sleep-in = [13 0a 00 01 28 13 78 00 01 10];
		sleep-out = [13 78 00 01 11 13 32 00 01 29];

		display-timings {
			clock-frequency = <0x704e0>;
			hactive = <0x1e0>;
			vactive = <0x1e0>;
			hback-porch = <0x18>;
			hfront-porch = <0x20>;
			hsync-len = <0x04>;
			vfront-porch = <0x08>;
			vback-porch = <0x04>;
			vsync-len = <0x02>;
		};

		oled-backlight {
			default-brightness = <0x19>;
			max-level = <0xff>;
			brightness-levels = <0x230a0002 0x5100230a 0x25101 0x230a0002 0x5102230a 0x25103 0x230a0002 0x5104230a 0x25105 0x230a0002 0x5106230a 0x25107 0x230a0002 0x5108230a 0x25109 0x230a0002 0x510a230a 0x2510b 0x230a0002 0x510c230a 0x2510d 0x230a0002 0x510e230a 0x2510f 0x230a0002 0x5110230a 0x25111 0x230a0002 0x5112230a 0x25113 0x230a0002 0x5114230a 0x25115 0x230a0002 0x5116230a 0x25117 0x230a0002 0x5118230a 0x25119 0x230a0002 0x511a230a 0x2511b 0x230a0002 0x511c230a 0x2511d 0x230a0002 0x511e230a 0x2511f 0x230a0002 0x5120230a 0x25121 0x230a0002 0x5122230a 0x25123 0x230a0002 0x5124230a 0x25125 0x230a0002 0x5126230a 0x25127 0x230a0002 0x5128230a 0x25129 0x230a0002 0x512a230a 0x2512b 0x230a0002 0x512c230a 0x2512d 0x230a0002 0x512e230a 0x2512f 0x230a0002 0x5130230a 0x25131 0x230a0002 0x5132230a 0x25133 0x230a0002 0x5134230a 0x25135 0x230a0002 0x5136230a 0x25137 0x230a0002 0x5138230a 0x25139 0x230a0002 0x513a230a 0x2513b 0x230a0002 0x513c230a 0x2513d 0x230a0002 0x513e230a 0x2513f 0x230a0002 0x5140230a 0x25141 0x230a0002 0x5142230a 0x25143 0x230a0002 0x5144230a 0x25145 0x230a0002 0x5146230a 0x25147 0x230a0002 0x5148230a 0x25149 0x230a0002 0x514a230a 0x2514b 0x230a0002 0x514c230a 0x2514d 0x230a0002 0x514e230a 0x2514f 0x230a0002 0x5150230a 0x25151 0x230a0002 0x5152230a 0x25153 0x230a0002 0x5154230a 0x25155 0x230a0002 0x5156230a 0x25157 0x230a0002 0x5158230a 0x25159 0x230a0002 0x515a230a 0x2515b 0x230a0002 0x515c230a 0x2515d 0x230a0002 0x515e230a 0x2515f 0x230a0002 0x5160230a 0x25161 0x230a0002 0x5162230a 0x25163 0x230a0002 0x5164230a 0x25165 0x230a0002 0x5166230a 0x25167 0x230a0002 0x5168230a 0x25169 0x230a0002 0x516a230a 0x2516b 0x230a0002 0x516c230a 0x2516d 0x230a0002 0x516e230a 0x2516f 0x230a0002 0x5170230a 0x25171 0x230a0002 0x5172230a 0x25173 0x230a0002 0x5174230a 0x25175 0x230a0002 0x5176230a 0x25177 0x230a0002 0x5178230a 0x25179 0x230a0002 0x517a230a 0x2517b 0x230a0002 0x517c230a 0x2517d 0x230a0002 0x517e230a 0x2517f 0x230a0002 0x5180230a 0x25181 0x230a0002 0x5182230a 0x25183 0x230a0002 0x5184230a 0x25185 0x230a0002 0x5186230a 0x25187 0x230a0002 0x5188230a 0x25189 0x230a0002 0x518a230a 0x2518b 0x230a0002 0x518c230a 0x2518d 0x230a0002 0x518e230a 0x2518f 0x230a0002 0x5190230a 0x25191 0x230a0002 0x5192230a 0x25193 0x230a0002 0x5194230a 0x25195 0x230a0002 0x5196230a 0x25197 0x230a0002 0x5198230a 0x25199 0x230a0002 0x519a230a 0x2519b 0x230a0002 0x519c230a 0x2519d 0x230a0002 0x519e230a 0x2519f 0x230a0002 0x51a0230a 0x251a1 0x230a0002 0x51a2230a 0x251a3 0x230a0002 0x51a4230a 0x251a5 0x230a0002 0x51a6230a 0x251a7 0x230a0002 0x51a8230a 0x251a9 0x230a0002 0x51aa230a 0x251ab 0x230a0002 0x51ac230a 0x251ad 0x230a0002 0x51ae230a 0x251af 0x230a0002 0x51b0230a 0x251b1 0x230a0002 0x51b2230a 0x251b3 0x230a0002 0x51b4230a 0x251b5 0x230a0002 0x51b6230a 0x251b7 0x230a0002 0x51b8230a 0x251b9 0x230a0002 0x51ba230a 0x251bb 0x230a0002 0x51bc230a 0x251bd 0x230a0002 0x51be230a 0x251bf 0x230a0002 0x51c0230a 0x251c1 0x230a0002 0x51c2230a 0x251c3 0x230a0002 0x51c4230a 0x251c5 0x230a0002 0x51c6230a 0x251c7 0x230a0002 0x51c8230a 0x251c9 0x230a0002 0x51ca230a 0x251cb 0x230a0002 0x51cc230a 0x251cd 0x230a0002 0x51ce230a 0x251cf 0x230a0002 0x51d0230a 0x251d1 0x230a0002 0x51d2230a 0x251d3 0x230a0002 0x51d4230a 0x251d5 0x230a0002 0x51d6230a 0x251d7 0x230a0002 0x51d8230a 0x251d9 0x230a0002 0x51da230a 0x251db 0x230a0002 0x51dc230a 0x251dd 0x230a0002 0x51de230a 0x251df 0x230a0002 0x51e0230a 0x251e1 0x230a0002 0x51e2230a 0x251e3 0x230a0002 0x51e4230a 0x251e5 0x230a0002 0x51e6230a 0x251e7 0x230a0002 0x51e8230a 0x251e9 0x230a0002 0x51ea230a 0x251eb 0x230a0002 0x51ec230a 0x251ed 0x230a0002 0x51ee230a 0x251ef 0x230a0002 0x51f0230a 0x251f1 0x230a0002 0x51f2230a 0x251f3 0x230a0002 0x51f4230a 0x251f5 0x230a0002 0x51f6230a 0x251f7 0x230a0002 0x51f8230a 0x251f9 0x230a0002 0x51fa230a 0x251fb 0x230a0002 0x51fc230a 0x251fd 0x230a0002 0x51fe230a 0x251ff>;
		};
	};

	mt108_lcdffff: lcdffff@ffff {
		work-mode = <0x01>;
		bpp = <0x18>;
		lane-number = <0x04>;
		fps = <0x3c>;
		panel-name = "lcd_dummy_mipi_hd";
		power-on-sequence = <0x7e 0x01 0x14 0x7e 0x00 0x14 0x7e 0x01 0x78>;
		power-off-sequence = <0x7e 0x00 0x14>;
		init-data = [13 78 00 01 11 13 64 00 01 29];
		sleep-in = [13 0a 00 01 28 13 78 00 01 10];
		sleep-out = [13 78 00 01 11 13 64 00 01 29];

		display-timings {
			clock-frequency = <0x7a120>;
			hactive = <0x2d0>;
			vactive = <0x500>;
			hback-porch = <0x1e>;
			hfront-porch = <0x28>;
			vback-porch = <0x06>;
			vfront-porch = <0x14>;
			hsync-len = <0x1e>;
			vsync-len = <0x04>;
		};
	};
